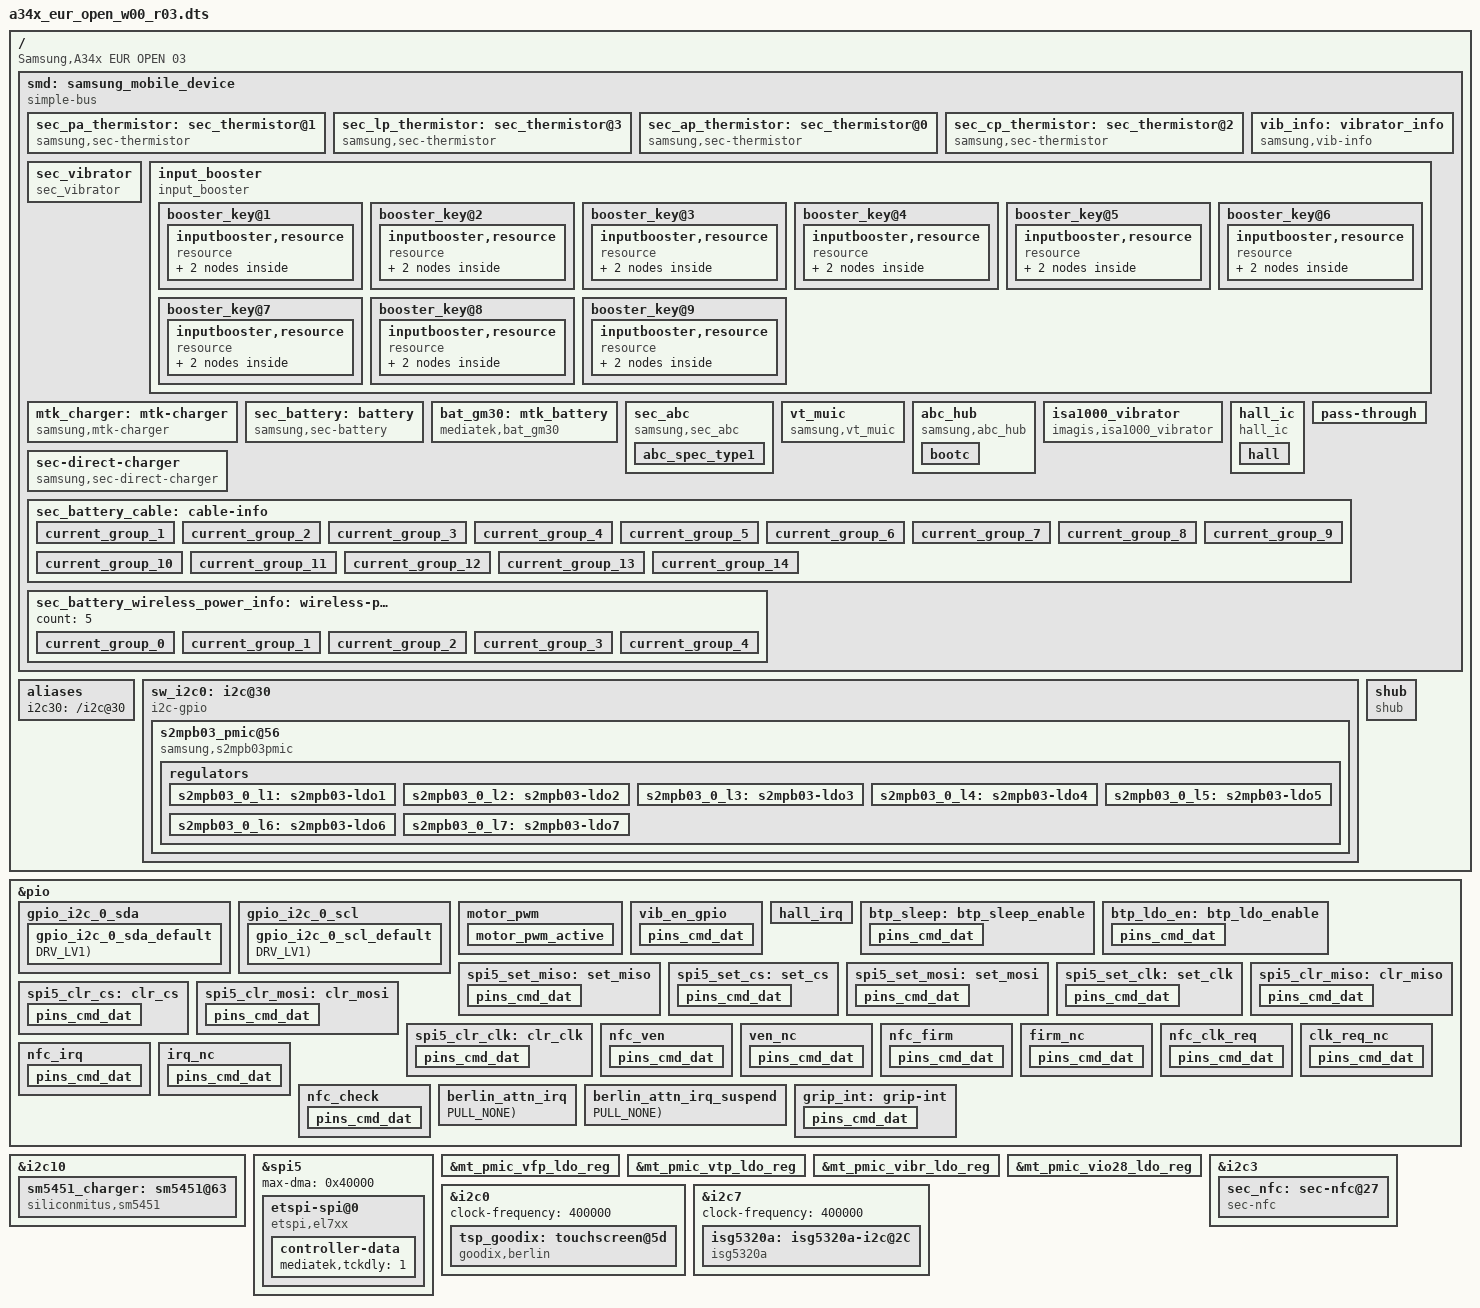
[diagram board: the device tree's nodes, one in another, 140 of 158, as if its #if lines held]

/*
 * Copyright (c) 2018 Samsung Electronics Co., Ltd.
 *              http://www.samsung.com
 *
 * This program is free software; you can redistribute it and/or modify
 * it under the terms of the GNU General Public License version 2 as
 * published by the Free Software Foundation.
*/

/dts-v1/;
/plugin/;
/ {
	fragment@smd {
		target-path = "/";
		__overlay__ {
			smd: samsung_mobile_device {
				compatible = "simple-bus";
			};
		};
	};
};

/* #include "../vibrator_vib_info.dtsi" */           /* From vibrator_vib_info.py */

&smd {
	vib_info: vibrator_info {
		status = "okay";
		compatible = "samsung,vib-info";
		functions = "INTENSITY";
#if 1
		samsung,intensities = <0 2000 4000 6000 8000 10000>;
#else
		samsung,intensities = <>;
#endif

#if 1
		samsung,haptic_intensities = <0 3000 4000 6000 8000 10000>;
#else
		samsung,haptic_intensities = <>;
#endif
	};
};

/* #include "../sec_vibrator.dtsi" */                /* From sec_vibrator.py */

&smd {
	sec_vibrator {
		status = "okay";
		compatible = "sec_vibrator";

		haptic,normal_ratio = <84>;
		haptic,high_temp_ref = <48>;
		haptic,high_temp_ratio = <71>;
	};
};


/* #include "../common/input_booster_mt6877.dtsi" */ /* From input_booster_mt6877.py */
/* Copyright (c) 2019, The Linux Foundation. All rights reserved.
 *
 * This program is free software; you can redistribute it and/or modify
 * it under the terms of the GNU General Public License version 2 and
 * only version 2 as published by the Free Software Foundation.
 *
 * This program is distributed in the hope that it will be useful,
 * but WITHOUT ANY WARRANTY; without even the implied warranty of
 * MERCHANTABILITY or FITNESS FOR A PARTICULAR PURPOSE.  See the
 * GNU General Public License for more details.
 */

&smd {
	input_booster {
		status = "okay";
		compatible = "input_booster";
		resValcount = "2";
		max_resource_count = "3";
		max_cluster_count = "3";
		#address-cells = <1>;
		#size-cells = <0>;

		/* Each Cpu Cluster Start Cpu */
		cpu_cluster_policy = "6,0";

		/* < CPU, DDR, SCHEDBOOST > */
		ib_release_values = "-1,16,0";

		/* Select Allowed Resource Index Group */
		allowed_resources = "0,1";

		booster_key@1 {
			input_booster,label = "key";
			input_booster,type = <0>;	/* BOOSTER_DEVICE_KEY */

			/* Time table */
			input_booster,head_time = <200>;
			input_booster,tail_time = <0>;

			/* Resource Table Sequentially identified with index
			 * CPU's ID & Index : 0
			 * DDR's ID & Index : 1
			*/

			/* Input Booster Resource Frequency */
			inputbooster,resource {
				compatible = "resource";
				resource@1 {
					resource,label = "CPU";
					resource,value = <1540000 0>;
				};

				resource@2 {
					resource,label = "DDR";
					resource,value = <0 0>;
				};
			};
		};

		booster_key@2 {
			input_booster,label = "touchkey";
			input_booster,type = <1>;	/* BOOSTER_DEVICE_TOUCHKEY */

			/* Time table */
			input_booster,head_time = <1>;
			input_booster,tail_time = <300>;

			/* Input Booster Resource Frequency */
			inputbooster,resource {
				compatible = "resource";
				resource@1 {
					resource,label = "CPU";
					resource,value = <0 1540000>;
				};

				resource@2 {
					resource,label = "DDR";
					resource,value = <0 0>;
				};
			};
		};

		booster_key@3 {
			input_booster,label = "touch";
			input_booster,type = <2>;	/* BOOSTER_DEVICE_TOUCH */

			/* Time table */
			input_booster,head_time = <130>;
			input_booster,tail_time = <500>;

			/* Input Booster Resource Frequency */
			inputbooster,resource {
				compatible = "resource";
				resource@1 {
					resource,label = "CPU";
					resource,value = <1140000 1075200>;
				};

				resource@2 {
					resource,label = "DDR";
					resource,value = <4266 4266>;
				};
			};
		};

		booster_key@4 {
			input_booster,label = "multitouch";
			input_booster,type = <3>;	/* BOOSTER_DEVICE_MULTITOUCH */

			/* Time table */
			input_booster,head_time = <1000>;
			input_booster,tail_time = <500>;

			/* Input Booster Resource Frequency */
			inputbooster,resource {
				compatible = "resource";
				resource@1 {
					resource,label = "CPU";
					resource,value = <1140000 1075200>;
				};

				resource@2 {
					resource,label = "DDR";
					resource,value = <4266 4266>;
				};
			};
		};

		booster_key@5 {
			input_booster,label = "keyboard";
			input_booster,type = <4>;	/* BOOSTER_DEVICE_KEYBOARD */

			/* Time table */
			input_booster,head_time = <130>;
			input_booster,tail_time = <130>;

			/* Input Booster Resource Frequency */
			inputbooster,resource {
				compatible = "resource";
				resource@1 {
					resource,label = "CPU";
					resource,value = <1430000 1040000>;
				};

				resource@2 {
					resource,label = "DDR";
					resource,value = <4266 4266>;
				};
			};
		};

		booster_key@6 {
			input_booster,label = "MOUSE";
			input_booster,type = <5>;	/* BOOSTER_DEVICE_MOUSE */

			/* Time table */
			input_booster,head_time = <200>;
			input_booster,tail_time = <300>;

			/* Input Booster Resource Frequency */
			inputbooster,resource {
				compatible = "resource";
				resource@1 {
					resource,label = "CPU";
					resource,value = <1430000 1040000>;
				};

				resource@2 {
					resource,label = "DDR";
					resource,value = <4266 4266>;
				};
			};
		};

		booster_key@7 {
			input_booster,label = "mouse_wheel";
			input_booster,type = <6>;	/* BOOSTER_DEVICE_MOUSE */

			/* Time table */
			input_booster,head_time = <200>;
			input_booster,tail_time = <0>;

			/* Input Booster Resource Frequency */
			inputbooster,resource {
				compatible = "resource";
				resource@1 {
					resource,label = "CPU";
					resource,value = <1430000 0>;
				};

				resource@2 {
					resource,label = "DDR";
					resource,value = <4266 0>;
				};
			};
		};

		booster_key@8 {
			input_booster,label = "pen_hover";
			input_booster,type = <7>;	/* BOOSTER_DEVICE_MOUSE */

			/* Time table */
			input_booster,head_time = <200>;
			input_booster,tail_time = <300>;

			/* Input Booster Resource Frequency */
			inputbooster,resource {
				compatible = "resource";
				resource@1 {
					resource,label = "CPU";
					resource,value = <1430000 1040000>;
				};

				resource@2 {
					resource,label = "DDR";
					resource,value = <0 0>;
				};
			};
		};

		booster_key@9 {
			input_booster,label = "pen";
			input_booster,type = <8>;	/* BOOSTER_DEVICE_MOUSE */

			/* Time table */
			input_booster,head_time = <200>;
			input_booster,tail_time = <600>;

			/* Input Booster Resource Frequency */
			inputbooster,resource {
				compatible = "resource";
				resource@1 {
					resource,label = "CPU";
					resource,value = <1800000 1040000>;
				};

				resource@2 {
					resource,label = "DDR";
					resource,value = <4266 4266>;
				};
			};
		};
		/* If you need to add new key type, add it this position */
	};
};

/* #include "../nc.dtsi" */                          /* From nc.py */
#define LEGO_IS_USE_NC
#define LEGO_IS_USE(x, ...) !defined(LEGO_IS_USE_##x)

/* #include "../sec_pinctrl_wrapper.dtsi" */         /* From sec_pinctrl_wrapper.py */
#define PIN_FUNC_INPUT		input-enable
#define PIN_FUNC_INPUT_WAKEUP	input-enable
#define PIN_FUNC_OUTPUT		output-enable
#define PIN_FUNC_OUTPUT_HIGH		output-high
#define PIN_FUNC_OUTPUT_LOW		output-low

#define PIN_PULL_NONE	bias-disable
#define PIN_PULL_DOWN	bias-pull-down
#define PIN_PULL_UP	bias-pull-up
#define PIN_PULL_OPEN	bias-high-impedance

/*
 * MTK_DRIVE_2mA  2
 * MTK_DRIVE_4mA  4
 * MTK_DRIVE_6mA  6
 * MTK_DRIVE_8mA  8
 * MTK_DRIVE_10mA 10
 * MTK_DRIVE_12mA 12
 * MTK_DRIVE_14mA 14
 * MTK_DRIVE_16mA 16
 */

#define PIN_DRV_LV1	2
#define PIN_DRV_LV2	4
#define PIN_DRV_LV3	6
#define PIN_DRV_LV4	8
#define PIN_DRV_LV5	10
#define PIN_DRV_LV6	12
#define PIN_DRV_LV7	14
#define PIN_DRV_LV8	16

#define PIN_EXPAND(pin) #pin

#define SEC_GPIO(src, type, num)	PIN_EXPAND(gpio##num)
#define SEC_GPIO_REF(src, type, num)	&type num
#define SEC_GPIO_NUM(src, type, num)	num
#define SEC_GPIO_TYPE(src, type, num)	&type
#define SEC_GPIO_PHANDLE_ACTIVE(src, type, num)	SEC_GPIO_PHANDLE(type, num, active)
#define SEC_GPIO_PHANDLE_SLEEP(src, type, num)	SEC_GPIO_PHANDLE(type, num, sleep)
#define SEC_GPIO_PHANDLE(type, num, mode)	type##_##num##_##mode

#define MTK_PINMUX(gpio, func) (MTK_PIN_NO(gpio) | func)

#define GPIO_CONFIG(_src, _type, _num, _func)		\
	pins_cmd_dat{					\
		pinmux = <MTK_PINMUX(SEC_GPIO_NUM(_src, _type, _num), 0)>;	\
		PIN_ ##_func;		\
	}

#define GPIO_CONFIG_PUD(_src, _type, _num, _func, _pull)	\
	pins_cmd_dat{					\
		pinmux = <MTK_PINMUX(SEC_GPIO_NUM(_src, _type, _num), 0)>;	\
		PIN_ ##_pull;				\
		PIN_ ##_func;		\
	}

#define GPIO_CONFIG_PUD_DRV(_src, _type, _num, _func, _pull, _drv)	\
	pins_cmd_dat{					\
		pinmux = <MTK_PINMUX(SEC_GPIO_NUM(_src, _type, _num), 0)>;	\
		PIN_ ##_pull;				\
		PIN_ ##_func;		\
		drive-strength = <PIN_ ##_drv>;	\
	}

#define SEC_ADC(type, num) <&type num>
#define SEC_ADC_OPT(type, num) ,<&type num>
#define SEC_ADC_NUM(type, num) <num>

/* #include "../mtk_charger.dtsi" */                 /* From mtk_charger.py */

&smd {
	mtk_charger: mtk-charger {
		compatible = "samsung,mtk-charger";
#if defined(CONFIG_SEC_FACTORY)
		charger,vbus_min_charger_voltage = <4200000>;
		charger,vbus_normal_mivr_voltage = <4200000>;
#else
		charger,vbus_min_charger_voltage = <4400000>;
		charger,vbus_normal_mivr_voltage = <4400000>;
#endif
		charger,gpio_ilim = <&pio 140 0x0>;
		charger,gpio_chgenb = <&pio 135 0x0>;
		charger,max_icl = <3250>;
		charger,ib_fcc = <100>;
	};

	battery {
		battery,otg_name = "mtk-otg";
	};
};

/* /home/dpi/qb5_8814/workspace/P4_1716/android/kernel/kmodule/battery/suwon/charger/mtk_charger/mtk_charger.a34x.dtsi */

&smd {
	mtk_charger: mtk-charger {
		charger,gpio_chgenb = <&pio 142 0x0>;
		charger,chgilm_en = <0>;
	};
};

/* /home/dpi/qb5_8814/workspace/P4_1716/android/kernel/kmodule/battery/suwon/charger/mtk_charger/mtk_charger.a34x.01.dtsi */

&smd {
	mtk_charger: mtk-charger {
		charger,gpio_chgenb = <&pio 27 0x0>;
		charger,chgenb_en = <0>;
	};
};

/* #include "../mtk_fuelgauge.dtsi" */               /* From mtk_fuelgauge.py */
&smd {
	battery {
		battery,fuelgauge_name = "mtk-fg-battery";
	};

	/* battery_prop.dtsi */
	bat_gm30: mtk_battery{
		compatible = "mediatek,bat_gm30";
		DIFFERENCE_FULLOCV_ITH = <(300)>;
	/*	Charging termination current*/
		SHUTDOWN_1_TIME = <(60)>;
	/*	If ui_soc shows 1% more than X minites, system will shutdown*/
		KEEP_100_PERCENT = <(1)>;
	/*	The ui_soc will keep 100% until SOC drop X percents after unplugged */
		R_FG_VALUE = <(5)>;
	/*	R_sense resistance*/
		EMBEDDED_SEL = <(0)>;
	/*	Configures whether using embedded battery or not*/
		PMIC_SHUTDOWN_CURRENT = <(20)>;
	/*	System shutdown current*/
		FG_METER_RESISTANCE = <(100)>;
	/*	The resistance of PCB*/
		CAR_TUNE_VALUE = <(99)>;
	/*	Tune value for current measurement*/
		PMIC_MIN_VOL = <(33500)>;
	/*	vboot voltage for gauge 0%*/
		POWERON_SYSTEM_IBOOT = <(500)>;
	/*	power on system iboot*/
		SHUTDOWN_GAUGE0 = <(0)>;
	/*	Shutdown condition2 switch*/
		SHUTDOWN_GAUGE0_VOLTAGE = <(34000)>;
	/*	shutdown gauge 0% voltage*/
		TEMPERATURE_T0 = <(50)>;
	/*	Battery temperature T0*/
		TEMPERATURE_T1 = <(25)>;
	/*	Battery temperature T1*/
		TEMPERATURE_T2 = <(10)>;
	/*	Battery temperature T2*/
		TEMPERATURE_T3 = <(0)>;
	/*	Battery temperature T3*/
		TEMPERATURE_T4 = <(-10)>;
	/*	Battery temperature T4*/
		TEMPERATURE_T5 = <(-20)>;
	/*	Battery temperature T5*/
		g_FG_PSEUDO100_T0 = <(93)>;
	/*	Pseudo 100% percentage at T0*/
		g_FG_PSEUDO100_T1 = <(93)>;
	/*	Pseudo 100% percentage at T1*/
		g_FG_PSEUDO100_T2 = <(93)>;
	/*	Pseudo 100% percentage at T2*/
		g_FG_PSEUDO100_T3 = <(93)>;
	/*	Pseudo 100% percentage at T3*/
		g_FG_PSEUDO100_T4 = <(93)>;
	/*	Pseudo 100% percentage at T4*/
		g_FG_PSEUDO100_T5 = <(93)>;
	/*	Pseudo 100% percentage at T4*/
		Q_MAX_SYS_VOLTAGE_BAT0 = <(3350)>;
	/*	Pseudo1 for hide percentage*/
		Q_MAX_SYS_VOLTAGE_BAT1 = <(3350)>;
	/*	Pseudo1 for hide percentage*/
		Q_MAX_SYS_VOLTAGE_BAT2 = <(3350)>;
	/*	Pseudo1 for hide percentage*/
		Q_MAX_SYS_VOLTAGE_BAT3 = <(3350)>;
	/*	Pseudo1 for hide percentage*/
		COM_FG_METER_RESISTANCE = <(100)>;
	/*	compensate The resistance of PCB*/
		COM_R_FG_VALUE = <(0)>;
	/*	compensate R_sense resistance*/
		enable_tmp_intr_suspend = <(0)>;
	/* Enable update temp when suspend */
		ACTIVE_TABLE = <(6)>;
	/* Table numbers per battery*/
		MULTI_TEMP_GAUGE0 = <(1)>;
	/* Multi gauge0 enable*/
		HWOCV_OLDOCV_DIFF = <(100)>;
	/* Diff of HWOCV and SWOCV*/

	/* battery_table.dtsi*/
	battery0_profile_t0_num = <100>;
	battery0_profile_t0_col = <3>;
	battery0_profile_t0 =
	<
	0       43520   850
	486     43380   866
	972     43251   875
	1458    43130   897
	1944    43004   875
	2430    42881   875
	2916    42760   875
	3402    42644   875
	3888    42530   900
	4375    42407   875
	4861    42293   881
	5347    42178   900
	5833    42054   875
	6319    41941   897
	6805    41820   875
	7291    41714   875
	7777    41601   900
	8263    41485   875
	8749    41372   875
	9235    41267   897
	9721    41155   875
	10207   41051   875
	10693   40945   875
	11179   40837   884
	11665   40739   875
	12152   40642   900
	12638   40542   894
	13124   40446   919
	13610   40350   900
	14096   40253   900
	14582   40162   919
	15068   40070   925
	15554   39979   925
	16040   39898   941
	16526   39817   950
	17012   39736   950
	17498   39655   962
	17984   39573   975
	18470   39492   975
	18956   39411   1000
	19442   39329   1025
	19928   39210   975
	20415   39078   938
	20901   38949   878
	21387   38849   875
	21873   38773   850
	22359   38699   850
	22845   38635   850
	23331   38580   850
	23817   38521   850
	24303   38472   850
	24789   38423   850
	25275   38374   875
	25761   38326   850
	26247   38285   869
	26733   38239   850
	27219   38200   875
	27705   38157   866
	28192   38115   868
	28678   38082   872
	29164   38050   875
	29650   38007   853
	30136   37975   875
	30622   37952   900
	31108   37919   900
	31594   37887   900
	32080   37865   907
	32566   37841   925
	33052   37810   925
	33538   37765   900
	34024   37684   861
	34510   37614   865
	34996   37550   851
	35482   37511   859
	35968   37465   857
	36455   37424   853
	36941   37374   850
	37427   37337   875
	37913   37304   875
	38399   37272   875
	38885   37230   875
	39371   37185   900
	39857   37120   875
	40343   37063   875
	40829   37004   888
	41315   36942   879
	41801   36861   881
	42287   36806   860
	42773   36790   875
	43259   36780   891
	43745   36767   907
	44232   36751   948
	44718   36719   976
	45204   36643   1018
	45690   36372   937
	46176   35944   969
	46662   35387   1000
	47148   34581   1041
	47634   33318   1181
	48120   30130   10325
	>;
	battery0_profile_t1_num = <100>;
	battery0_profile_t1_col = <3>;
	battery0_profile_t1 =
	<
	0       43320   1450
	486     43164   1450
	972     43033   1475
	1458    42911   1475
	1944    42789   1475
	2430    42671   1475
	2916    42550   1456
	3402    42434   1475
	3888    42320   1475
	4375    42197   1440
	4861    42083   1431
	5347    41968   1428
	5833    41854   1437
	6319    41741   1428
	6805    41628   1431
	7291    41514   1425
	7777    41401   1425
	8263    41295   1425
	8749    41184   1407
	9235    41078   1403
	9721    40975   1412
	10207   40871   1425
	10693   40765   1425
	11179   40667   1416
	11665   40569   1425
	12152   40475   1450
	12638   40382   1450
	13124   40277   1450
	13610   40190   1450
	14096   40093   1447
	14582   40002   1444
	15068   39920   1460
	15554   39839   1450
	16040   39758   1450
	16526   39687   1500
	17012   39606   1500
	17498   39525   1500
	17984   39443   1504
	18470   39354   1525
	18956   39243   1490
	19442   39109   1425
	19928   38980   1344
	20415   38875   1319
	20901   38787   1300
	21387   38719   1313
	21873   38654   1300
	22359   38589   1300
	22845   38535   1290
	23331   38480   1300
	23817   38431   1291
	24303   38384   1300
	24789   38343   1300
	25275   38294   1300
	25761   38257   1303
	26247   38217   1325
	26733   38182   1309
	27219   38140   1325
	27705   38107   1341
	28192   38075   1332
	28678   38042   1350
	29164   38010   1350
	29650   37987   1375
	30136   37955   1375
	30622   37926   1375
	31108   37900   1376
	31594   37877   1384
	32080   37855   1400
	32566   37822   1378
	33052   37790   1375
	33538   37747   1375
	34024   37707   1356
	34510   37672   1360
	34996   37630   1351
	35482   37591   1359
	35968   37552   1350
	36455   37512   1372
	36941   37480   1375
	37427   37447   1375
	37913   37414   1394
	38399   37368   1385
	38885   37310   1376
	39371   37248   1393
	39857   37192   1400
	40343   37134   1423
	40829   37063   1412
	41315   36975   1425
	41801   36935   1425
	42287   36920   1460
	42773   36910   1475
	43259   36894   1500
	43745   36867   1514
	44232   36833   1573
	44718   36727   1613
	45204   36421   1607
	45690   35937   1688
	46176   35299   1804
	46662   34415   1951
	47148   32710   2488
	47634   30570   11550
	48120   30570   11550
	>;
	battery0_profile_t2_num = <100>;
	battery0_profile_t2_col = <3>;
	battery0_profile_t2 =
	<
	0       43000   3200
	486     42808   3293
	972     42661   3412
	1458    42531   3472
	1944    42404   3476
	2430    42281   3478
	2916    42160   3481
	3402    42044   3484
	3888    41930   3475
	4375    41817   3485
	4861    41695   3456
	5347    41579   3431
	5833    41474   3450
	6319    41361   3425
	6805    41255   3425
	7291    41144   3425
	7777    41041   3425
	8263    40931   3416
	8749    40834   3407
	9235    40737   3425
	9721    40640   3425
	10207   40541   3444
	10693   40435   3419
	11179   40337   3425
	11665   40229   3375
	12152   40138   3391
	12638   40047   3381
	13124   39957   3378
	13610   39875   3400
	14096   39794   3375
	14582   39712   3375
	15068   39640   3415
	15554   39559   3425
	16040   39472   3409
	16526   39382   3425
	17012   39269   3381
	17498   39146   3350
	17984   39008   3268
	18470   38894   3225
	18956   38801   3200
	19442   38720   3200
	19928   38655   3200
	20415   38590   3200
	20901   38534   3222
	21387   38479   3225
	21873   38426   3250
	22359   38377   3250
	22845   38329   3275
	23331   38280   3275
	23817   38241   3300
	24303   38202   3325
	24789   38162   3347
	25275   38130   3363
	25761   38087   3378
	26247   38055   3400
	26733   38022   3425
	27219   37990   3425
	27705   37967   3466
	28192   37935   3500
	28678   37911   3500
	29164   37885   3525
	29650   37859   3528
	30136   37842   3569
	30622   37822   3600
	31108   37800   3601
	31594   37784   3641
	32080   37757   3657
	32566   37732   3697
	33052   37700   3700
	33538   37667   3728
	34024   37627   3750
	34510   37592   3795
	34996   37559   3850
	35482   37517   3866
	35968   37482   3932
	36455   37434   3972
	36941   37374   4026
	37427   37314   4104
	37913   37249   4144
	38399   37190   4235
	38885   37119   4325
	39371   37028   4398
	39857   36965   4501
	40343   36932   4666
	40829   36905   4816
	41315   36877   5048
	41801   36845   5310
	42287   36790   5653
	42773   36689   6028
	43259   36466   6433
	43745   36033   6914
	44232   35419   7720
	44718   34544   8974
	45204   33115   11297
	45690   30950   12525
	46176   30950   12525
	46662   30950   12525
	47148   30950   12525
	47634   30950   12525
	48120   30950   12525
	>;
	battery0_profile_t3_num = <100>;
	battery0_profile_t3_col = <3>;
	battery0_profile_t3 =
	<
	0       42520   5950
	486     42262   6183
	972     42098   6518
	1458    41961   6640
	1944    41824   6714
	2430    41701   6753
	2916    41580   6775
	3402    41464   6816
	3888    41350   6825
	4375    41237   6840
	4861    41123   6825
	5347    41017   6847
	5833    40909   6825
	6319    40812   6847
	6805    40715   6844
	7291    40604   6825
	7777    40501   6825
	8263    40385   6784
	8749    40274   6782
	9235    40177   6800
	9721    40080   6800
	10207   39984   6778
	10693   39903   6781
	11179   39821   6784
	11665   39739   6800
	12152   39658   6791
	12638   39587   6825
	13124   39497   6803
	13610   39410   6813
	14096   39312   6797
	14582   39196   6756
	15068   39069   6680
	15554   38949   6625
	16040   38836   6584
	16526   38747   6569
	17012   38666   6550
	17498   38600   6575
	17984   38536   6579
	18470   38479   6600
	18956   38418   6635
	19442   38370   6675
	19928   38321   6691
	20415   38275   6706
	20901   38234   6725
	21387   38194   6750
	21873   38156   6775
	22359   38115   6794
	22845   38082   6835
	23331   38050   6850
	23817   38018   6891
	24303   37984   6907
	24789   37952   6925
	25275   37930   6975
	25761   37909   7003
	26247   37892   7044
	26733   37876   7084
	27219   37860   7125
	27705   37843   7183
	28192   37827   7214
	28678   37811   7295
	29164   37795   7351
	29650   37777   7407
	30136   37752   7488
	30622   37722   7544
	31108   37689   7626
	31594   37657   7723
	32080   37622   7813
	32566   37582   7939
	33052   37540   8076
	33538   37495   8238
	34024   37437   8422
	34510   37374   8610
	34996   37309   8853
	35482   37238   9080
	35968   37170   9352
	36455   37096   9676
	36941   37004   10017
	37427   36935   10393
	37913   36894   10858
	38399   36862   11389
	38885   36830   11982
	39371   36791   12670
	39857   36740   13453
	40343   36656   14301
	40829   36424   15025
	41315   35986   15823
	41801   35349   16953
	42287   34442   18475
	42773   33430   18575
	43259   33430   18575
	43745   33430   18575
	44232   33430   18575
	44718   33430   18575
	45204   33430   18575
	45690   33430   18575
	46176   33430   18575
	46662   33430   18575
	47148   33430   18575
	47634   33430   18575
	48120   33430   18575
	>;
	battery0_profile_t4_num = <100>;
	battery0_profile_t4_col = <3>;
	battery0_profile_t4 =
	<
	0       42010   11330
	486     41738   11604
	972     41429   12066
	1458    41171   12469
	1944    40989   12751
	2430    40838   12878
	2916    40700   12919
	3402    40570   12916
	3888    40440   12875
	4375    40311   12819
	4861    40181   12744
	5347    40058   12703
	5833    39949   12675
	6319    39842   12650
	6805    39745   12650
	7291    39648   12616
	7777    39541   12526
	8263    39441   12509
	8749    39332   12437
	9235    39227   12378
	9721    39115   12312
	10207   39013   12272
	10693   38923   12250
	11179   38841   12216
	11665   38759   12200
	12152   38694   12184
	12638   38622   12175
	13124   38565   12175
	13610   38510   12200
	14096   38456   12178
	14582   38407   12200
	15068   38358   12210
	15554   38310   12225
	16040   38261   12241
	16526   38215   12256
	17012   38174   12297
	17498   38140   12325
	17984   38097   12329
	18470   38065   12350
	18956   38032   12375
	19442   38010   12450
	19928   37977   12475
	20415   37955   12506
	20901   37931   12568
	21387   37905   12626
	21873   37874   12675
	22359   37855   12770
	22845   37832   12819
	23331   37800   12900
	23817   37778   13031
	24303   37744   13121
	24789   37712   13242
	25275   37670   13327
	25761   37626   13460
	26247   37577   13639
	26733   37535   13728
	27219   37480   13875
	27705   37420   14031
	28192   37359   14202
	28678   37294   14386
	29164   37230   14552
	29650   37155   14720
	30136   37090   14944
	30622   37028   15148
	31108   36979   15354
	31594   36947   15613
	32080   36905   15847
	32566   36863   16130
	33052   36790   16376
	33538   36673   16644
	34024   36429   16891
	34510   36018   17215
	34996   35399   17761
	35482   34431   18699
	35968   32802   17069
	36455   31080   12750
	36941   31080   12750
	37427   31080   12750
	37913   31080   12750
	38399   31080   12750
	38885   31080   12750
	39371   31080   12750
	39857   31080   12750
	40343   31080   12750
	40829   31080   12750
	41315   31080   12750
	41801   31080   12750
	42287   31080   12750
	42773   31080   12750
	43259   31080   12750
	43745   31080   12750
	44232   31080   12750
	44718   31080   12750
	45204   31080   12750
	45690   31080   12750
	46176   31080   12750
	46662   31080   12750
	47148   31080   12750
	47634   31080   12750
	48120   31080   12750
	>;
	battery0_profile_t5_num = <100>;
	battery0_profile_t5_col = <3>;
	battery0_profile_t5 =
	<
	0       40920   10780
	483     40610   11233
	967     40337   12231
	1450    40095   12975
	1933    39872   13686
	2417    39674   14479
	2900    39510   15208
	3383    39378   15667
	3867    39258   15931
	4350    39150   16075
	4833    39042   16178
	5317    38929   16164
	5800    38830   16208
	6283    38733   16319
	6767    38652   16378
	7250    38573   16404
	7733    38509   16464
	8217    38444   16519
	8700    38390   16625
	9183    38335   16666
	9667    38292   16706
	10150   38244   16725
	10633   38200   16750
	11117   38158   16752
	11600   38126   16810
	12083   38087   16833
	12567   38052   16965
	13050   38019   16990
	13533   37987   17100
	14017   37955   17176
	14500   37919   17218
	14983   37880   17323
	15467   37838   17390
	15950   37794   17510
	16433   37738   17550
	16917   37683   17714
	17400   37629   17828
	17883   37564   17981
	18367   37500   18070
	18850   37427   18222
	19333   37361   18385
	19817   37286   18407
	20300   37222   18563
	20783   37158   18764
	21267   37093   18919
	21750   37039   19080
	22233   36974   19247
	22717   36910   19451
	23200   36824   19655
	23683   36692   19921
	24167   36470   20134
	24650   36118   20420
	25133   35546   20803
	25617   34662   21167
	26100   33270   18200
	26583   32530   16450
	27067   32530   16450
	27550   32530   16450
	28033   32530   16450
	28517   32530   16450
	29000   32530   16450
	29483   32530   16450
	29967   32530   16450
	30450   32530   16450
	30933   32530   16450
	31417   32530   16450
	31900   32530   16450
	32383   32530   16450
	32867   32530   16450
	33350   32530   16450
	33833   32530   16450
	34317   32530   16450
	34800   32530   16450
	35283   32530   16450
	35767   32530   16450
	36250   32530   16450
	36733   32530   16450
	37217   32530   16450
	37700   32530   16450
	38183   32530   16450
	38667   32530   16450
	39150   32530   16450
	39633   32530   16450
	40117   32530   16450
	40600   32530   16450
	41083   32530   16450
	41567   32530   16450
	42050   32530   16450
	42533   32530   16450
	43017   32530   16450
	43500   32530   16450
	43983   32530   16450
	44467   32530   16450
	44950   32530   16450
	45433   32530   16450
	45917   32530   16450
	46400   32530   16450
	46883   32530   16450
	47367   32530   16450
	47850   32530   16450
	>;

	/* battery_prop_dim2_ext.dtsi */
	/*vboot voltage for gauge 0%*/
	g_PMIC_MIN_VOL_row = <4>;
	g_PMIC_MIN_VOL_col = <10>;
	g_PMIC_MIN_VOL =
	<
		32700  32700  32700  32700
		32700  32700  32700  32700
		32700  32700  32700  32700
		32200  32200  32200  32200
		31000  31000  31000  31000
		31500  31500  31500  31500
		31000  31000  31000  31000
		31000  31000  31000  31000
		31000  31000  31000  31000
		31000  31000  31000  31200
	>;
	/*boot_up current for gauge 0%*/
	g_PON_SYS_IBOOT_row = <4>;
	g_PON_SYS_IBOOT_col = <10>;
	g_PON_SYS_IBOOT =
	<
		5000  5000  5000  5000
		5000  5000  5000  5000
		5000  5000  5000  5000
		5000  5000  5000  5000
		5000  5000  5000  5000
		5000  5000  5000  5000
		5000  5000  5000  5000
		5000  5000  5000  5000
		5000  5000  5000  5000
		5000  5000  5000  5000
	>;
	/*Pseudo1 hide percentage*/
	g_QMAX_SYS_VOL_row = <4>;
	g_QMAX_SYS_VOL_col = <10>;
	g_QMAX_SYS_VOL =
	<
		33600  33600  33600  33600
		33600  33600  33600  33600
		33600  33600  33600  33600
		33600  33600  33600  33600
		33600  33600  33600  33600
		32500  32500  32500  32500
		32800  32800  32800  32800
		32800  32800  32800  32800
		32800  32800  32800  32800
		32800  32800  32800  32800
	>;
	/*Pseudo100 percentage setting*/
	g_FG_PSEUDO100_row = <4>;
	g_FG_PSEUDO100_col = <10>;
	g_FG_PSEUDO100 =
	<
		91  100  100  100
		91  100  100  100
		91  100  100  100
		91  100  100  100
		91  100  100  100
		91  100  100  100
		100  100  100  100
		100  100  100  100
		100  100  100  100
		100  100  100  100
	>;

	};
};

/* /home/dpi/qb5_8814/workspace/P4_1716/android/kernel/kmodule/battery/suwon/fuelgauge/mtk_fuelgauge/mtk_fuelgauge.a34x.dtsi */
&smd {
	battery {
		battery,fuelgauge_name = "mtk-fg-battery";
	};

	/* battery_prop.dtsi */
bat_gm30: mtk_battery{
	compatible = "mediatek,bat_gm30";

	RBAT_TYPE = <(100)>;
	RBAT_PULL_UP_R = <(100000)>;

	rbat_temperature_table_num = <21>;
	rbat_battery_temperature =
	<
		(-40) 4397119
		(-35) 3088598
		(-30) 2197225
		(-25) 1581880
		(-20) 1151036
		(-15) 846578
		(-10) 628988
		(-5) 471632
		0 357011
		5 272499
		10 209709
		15 162650
		20 127080
		25 100000
		30 79221
		35 63167
		40 50676
		45 40903
		50 33194
		55 27090
		60 22224 >;
/* battery temperature table type - NTC table */
	BatteryID_GPIO_1 = <&pio 21 0>;
	BatteryID_GPIO = <&pio 22 0>;
/* Battery ID distinction */
	DIFFERENCE_FULLOCV_ITH = <(300)>; /* M53 : 250mA +50mA */
/*	Charging termination current*/
	SHUTDOWN_1_TIME = <(60)>;
/*	If ui_soc shows 1% more than X minites, system will shutdown*/
	KEEP_100_PERCENT = <(1)>;
/*	The ui_soc will keep 100% until SOC drop X percents after unplugged*/
	R_FG_VALUE = <(5)>;
/*	R_sense resistance*/
	EMBEDDED_SEL = <(0)>;
/*	Configures whether using embedded battery or not*/
	PMIC_SHUTDOWN_CURRENT = <(20)>;
/*	System shutdown current*/
	FG_METER_RESISTANCE = <(100)>;
/*	The resistance of PCB*/
	CAR_TUNE_VALUE = <(98)>;
/*	Tune value for current measurement*/
	PMIC_MIN_VOL = <(33500)>;
/*	vboot voltage for gauge 0%*/
	POWERON_SYSTEM_IBOOT = <(500)>;
/*	power on system iboot*/
	SHUTDOWN_GAUGE0 = <(0)>;
/*	Shutdown condition2 switch*/
	SHUTDOWN_GAUGE0_VOLTAGE = <(34000)>;
/*	shutdown gauge 0% voltage*/
	TEMPERATURE_T0 = <(50)>;
/*	Battery temperature T0*/
	TEMPERATURE_T1 = <(25)>;
/*	Battery temperature T1*/
	TEMPERATURE_T2 = <(10)>;
/*	Battery temperature T2*/
	TEMPERATURE_T3 = <(0)>;
/*	Battery temperature T3*/
	TEMPERATURE_T4 = <(-10)>;
/*	Battery temperature T4*/
	TEMPERATURE_T5 = <(-20)>;
/*	Battery temperature T5*/
	g_FG_PSEUDO100_T0 = <(100)>;
/*	Pseudo 100% percentage at T0*/
	g_FG_PSEUDO100_T1 = <(100)>;
/*	Pseudo 100% percentage at T1*/
	g_FG_PSEUDO100_T2 = <(100)>;
/*	Pseudo 100% percentage at T2*/
	g_FG_PSEUDO100_T3 = <(100)>;
/*	Pseudo 100% percentage at T3*/
	g_FG_PSEUDO100_T4 = <(100)>;
/*	Pseudo 100% percentage at T4*/
	g_FG_PSEUDO100_T5 = <(100)>;
/*	Pseudo 100% percentage at T4*/
	Q_MAX_SYS_VOLTAGE_BAT0 = <(3350)>;
/*	Pseudo1 for hide percentage*/
	Q_MAX_SYS_VOLTAGE_BAT1 = <(3350)>;
/*	Pseudo1 for hide percentage*/
	Q_MAX_SYS_VOLTAGE_BAT2 = <(3350)>;
/*	Pseudo1 for hide percentage*/
	Q_MAX_SYS_VOLTAGE_BAT3 = <(3350)>;
/*	Pseudo1 for hide percentage*/
	COM_FG_METER_RESISTANCE = <(100)>;
/*	compensate The resistance of PCB*/
	COM_R_FG_VALUE = <(0)>;
/*	compensate R_sense resistance*/
	enable_tmp_intr_suspend = <(0)>;
/* Enable update temp when suspend */
	ACTIVE_TABLE = <(6)>;
/* Table numbers per battery*/
	MULTI_TEMP_GAUGE0 = <(1)>;
/* Multi gauge0 enable*/
	HWOCV_OLDOCV_DIFF = <(100)>;
/* Diff of HWOCV and SWOCV*/
	UI_FULL_LIMIT_EN = <(1)>;
	UI_FULL_LIMIT_SOC0 = <(9545)>;
	UI_FULL_LIMIT_ITH0 = <(12000)>;
	UI_FULL_LIMIT_SOC1 = <(9645)>;
	UI_FULL_LIMIT_ITH1 = <(10000)>;
	UI_FULL_LIMIT_SOC2 = <(9745)>;
	UI_FULL_LIMIT_ITH2 = <(8000)>;
	UI_FULL_LIMIT_SOC3 = <(9845)>;
	UI_FULL_LIMIT_ITH3 = <(6500)>;
	UI_FULL_LIMIT_SOC4 = <(9945)>;
	UI_FULL_LIMIT_ITH4 = <(5300)>;
/* Using current to limit uisoc in 100% case*/
	UI_LOW_LIMIT_EN = <(1)>;
	UI_LOW_LIMIT_SOC0 = <(100)>;
	UI_LOW_LIMIT_VTH0 = <(34000)>;
	UI_LOW_LIMIT_SOC1 = <(100)>;
	UI_LOW_LIMIT_VTH1 = <(34000)>;
	UI_LOW_LIMIT_SOC2 = <(100)>;
	UI_LOW_LIMIT_VTH2 = <(34000)>;
	UI_LOW_LIMIT_SOC3 = <(100)>;
	UI_LOW_LIMIT_VTH3 = <(34000)>;
	UI_LOW_LIMIT_SOC4 = <(100)>;
	UI_LOW_LIMIT_VTH4 = <(34000)>;
/* using voltage to limit uisoc in 1% case */
	DYNAMIC_CV_FACTOR = <(100)>;
/* Dynamic CV offset */
	CHARGER_IEOC = <(250)>;
/* Charger termination current for Dynamic CV */

/* battery_table.dtsi*/
battery0_profile_t0_num = <100>;
battery0_profile_t0_col = <3>;
battery0_profile_t0 =
<
0       43990   475
474     43854   475
948     43739   500
1423    43628   500
1897    43515   500
2371    43404   500
2845    43289   488
3320    43182   500
3794    43062   500
4268    42949   500
4742    42831   500
5217    42708   498
5691    42587   501
6165    42471   510
6639    42354   525
7114    42228   506
7588    42111   516
8062    41992   524
8536    41876   525
9011    41751   503
9485    41640   525
9959    41529   532
10433   41419   550
10908   41298   525
11382   41185   525
11856   41081   541
12330   40974   550
12805   40863   530
13279   40762   565
13753   40652   526
14227   40551   550
14702   40450   550
15176   40355   569
15650   40260   575
16124   40165   575
16598   40070   575
17073   39985   600
17547   39897   616
18021   39806   607
18495   39719   625
18970   39628   625
19444   39529   625
19918   39397   585
20392   39246   525
20867   39127   506
21341   39032   509
21815   38952   501
22289   38879   500
22764   38816   500
23238   38752   500
23712   38689   500
24186   38633   500
24661   38576   500
25135   38519   500
25609   38471   500
26083   38424   525
26558   38376   525
27032   38329   525
27506   38280   525
27980   38239   514
28455   38197   525
28929   38158   525
29403   38121   525
29877   38082   547
30352   38051   550
30826   38018   552
31300   37980   558
31774   37945   550
32248   37913   550
32723   37874   555
33197   37810   500
33671   37731   514
34145   37654   505
34620   37599   506
35094   37550   500
35568   37511   523
36042   37455   500
36517   37417   525
36991   37369   508
37465   37334   525
37939   37294   503
38414   37257   525
38888   37199   524
39362   37136   500
39836   37074   505
40311   37018   505
40785   36951   510
41259   36872   525
41733   36825   489
42208   36819   522
42682   36803   500
43156   36797   525
43630   36772   525
44105   36746   550
44579   36662   550
45053   36398   566
45527   36003   625
46002   35496   665
46476   34819   735
46950   33830   850
>;
battery0_profile_t1_num = <100>;
battery0_profile_t1_col = <3>;
battery0_profile_t1 =
<
0       43900   750
474     43774   750
948     43669   800
1423    43558   781
1897    43449   784
2371    43344   800
2845    43234   800
3320    43122   800
3794    43002   800
4268    42889   800
4742    42771   800
5217    42648   800
5691    42527   801
6165    42411   810
6639    42286   800
7114    42168   800
7588    42051   800
8062    41932   800
8536    41811   800
9011    41701   803
9485    41583   807
9959    41469   807
10433   41359   825
10908   41248   825
11382   41135   825
11856   41031   841
12330   40924   850
12805   40813   850
13279   40712   850
13753   40611   874
14227   40511   875
14702   40410   879
15176   40307   881
15650   40210   883
16124   40115   900
16598   40030   925
17073   39935   925
17547   39847   925
18021   39754   925
18495   39667   946
18970   39564   925
19444   39459   924
19918   39317   845
20392   39186   796
20867   39075   775
21341   38982   741
21815   38912   749
22289   38839   738
22764   38776   750
23238   38712   733
23712   38659   743
24186   38603   747
24661   38546   725
25135   38499   750
25609   38451   750
26083   38404   750
26558   38356   750
27032   38319   750
27506   38270   750
27980   38233   750
28455   38196   771
28929   38155   750
29403   38124   775
29877   38092   797
30352   38061   787
30826   38028   798
31300   37997   792
31774   37965   800
32248   37933   779
32723   37902   800
33197   37860   775
33671   37817   761
34145   37766   750
34620   37727   750
35094   37690   750
35568   37642   727
36042   37595   725
36517   37558   727
36991   37519   733
37465   37484   750
37939   37453   750
38414   37407   750
38888   37349   750
39362   37286   750
39836   37234   755
40311   37178   775
40785   37101   750
41259   37022   774
41733   36975   764
42208   36960   775
42682   36953   775
43156   36937   782
43630   36921   822
44105   36886   825
44579   36822   873
45053   36575   866
45527   36160   911
46002   35630   990
46476   34925   1123
46950   33930   1425
>;
battery0_profile_t2_num = <100>;
battery0_profile_t2_col = <3>;
battery0_profile_t2 =
<
0       43620   1525
474     43458   1554
948     43337   1625
1423    43218   1644
1897    43095   1659
2371    42975   1675
2845    42859   1675
3320    42742   1675
3794    42622   1692
4268    42499   1675
4742    42381   1696
5217    42259   1686
5691    42137   1675
6165    42017   1675
6639    41904   1695
7114    41785   1675
7588    41671   1691
8062    41554   1699
8536    41442   1700
9011    41331   1725
9485    41220   1707
9959    41109   1725
10433   40999   1725
10908   40892   1725
11382   40788   1726
11856   40685   1750
12330   40584   1775
12805   40481   1775
13279   40376   1785
13753   40281   1800
14227   40177   1800
14702   40082   1800
15176   39985   1819
15650   39890   1825
16124   39786   1802
16598   39685   1813
17073   39563   1771
17547   39421   1709
18021   39290   1644
18495   39170   1604
18970   39074   1589
19444   38989   1550
19918   38920   1560
20392   38851   1571
20867   38780   1550
21341   38720   1559
21815   38662   1551
22289   38609   1575
22764   38557   1578
23238   38502   1583
23712   38452   1575
24186   38404   1596
24661   38356   1600
25135   38319   1625
25609   38271   1609
26083   38234   1625
26558   38186   1625
27032   38153   1650
27506   38121   1650
27980   38079   1650
28455   38047   1675
28929   38015   1675
29403   37984   1675
29877   37952   1697
30352   37921   1700
30826   37889   1676
31300   37857   1700
31774   37825   1700
32248   37793   1700
32723   37752   1685
33197   37710   1675
33671   37673   1700
34145   37627   1704
34620   37595   1725
35094   37554   1725
35568   37522   1747
36042   37476   1787
36517   37418   1800
36991   37353   1817
37465   37292   1831
37939   37245   1871
38414   37174   1885
38888   37090   1900
39362   37023   1925
39836   36998   1958
40311   36983   2018
40785   36957   2041
41259   36941   2097
41733   36916   2162
42208   36866   2256
42682   36714   2366
43156   36354   2472
43630   35840   2650
44105   35152   2943
44579   34223   3399
45053   33330   3975
45527   33330   3975
46002   33330   3975
46476   33330   3975
46950   33330   3975
>;
battery0_profile_t3_num = <100>;
battery0_profile_t3_col = <3>;
battery0_profile_t3 =
<
0       43160   3150
474     42932   3252
948     42785   3379
1423    42651   3456
1897    42521   3525
2371    42395   3548
2845    42269   3563
3320    42152   3600
3794    42026   3600
4268    41909   3625
4742    41791   3646
5217    41668   3650
5691    41547   3651
6165    41437   3675
6639    41326   3655
7114    41215   3675
7588    41105   3716
8062    40992   3700
8536    40881   3714
9011    40781   3722
9485    40670   3754
9959    40569   3825
10433   40459   3781
10908   40358   3789
11382   40256   3825
11856   40154   3825
12330   40056   3825
12805   39961   3845
13279   39862   3840
13753   39761   3825
14227   39661   3850
14702   39546   3821
15176   39420   3781
15650   39283   3717
16124   39157   3654
16598   39050   3638
17073   38956   3625
17547   38877   3641
18021   38806   3675
18495   38736   3675
18970   38673   3700
19444   38610   3700
19918   38556   3740
20392   38495   3754
20867   38447   3775
21341   38399   3825
21815   38351   3849
22289   38299   3877
22764   38257   3903
23238   38209   3925
23712   38172   3957
24186   38123   3997
24661   38091   4037
25135   38059   4075
25609   38017   4107
26083   37986   4130
26558   37954   4170
27032   37923   4209
27506   37890   4225
27980   37869   4264
28455   37849   4307
28929   37825   4350
29403   37804   4408
29877   37772   4447
30352   37751   4537
30826   37718   4604
31300   37687   4700
31774   37645   4762
32248   37605   4841
32723   37562   4956
33197   37510   5049
33671   37467   5193
34145   37404   5318
34620   37349   5477
35094   37283   5626
35568   37213   5791
36042   37140   5964
36517   37056   6138
36991   36992   6379
37465   36941   6643
37939   36903   6923
38414   36871   7261
38888   36839   7683
39362   36792   8218
39836   36715   8889
40311   36555   9692
40785   36264   10658
41259   35821   11990
41733   35195   14328
42208   34350   17484
42682   33770   19475
43156   33770   19475
43630   33770   19475
44105   33770   19475
44579   33770   19475
45053   33770   19475
45527   33770   19475
46002   33770   19475
46476   33770   19475
46950   33770   19475
>;
battery0_profile_t4_num = <100>;
battery0_profile_t4_col = <3>;
battery0_profile_t4 =
<
0       42820   4925
474     42510   5085
948     42181   5548
1423    41919   6185
1897    41721   6596
2371    41556   6912
2845    41413   7051
3320    41282   7127
3794    41156   7184
4268    41029   7232
4742    40903   7292
5217    40784   7361
5691    40657   7401
6165    40524   7440
6639    40392   7470
7114    40258   7469
7588    40121   7459
8062    39992   7426
8536    39866   7464
9011    39741   7453
9485    39623   7457
9959    39509   7475
10433   39399   7475
10908   39302   7475
11382   39206   7521
11856   39121   7524
12330   39038   7581
12805   38959   7620
13279   38884   7660
13753   38821   7699
14227   38748   7728
14702   38683   7784
15176   38620   7844
15650   38557   7883
16124   38493   7923
16598   38440   8000
17073   38387   8050
17547   38330   8066
18021   38279   8118
18495   38224   8164
18970   38177   8222
19444   38130   8276
19918   38092   8360
20392   38045   8400
20867   38005   8457
21341   37963   8534
21815   37931   8598
22289   37899   8702
22764   37868   8808
23238   37829   8910
23712   37792   9052
24186   37752   9236
24661   37711   9409
25135   37669   9581
25609   37615   9779
26083   37564   10007
26558   37508   10244
27032   37455   10472
27506   37381   10649
27980   37317   10871
28455   37254   11126
28929   37191   11366
29403   37131   11687
29877   37074   11981
30352   37026   12322
30826   36977   12599
31300   36920   13050
31774   36860   13431
32248   36780   13786
32723   36653   14163
33197   36481   14523
33671   36222   14878
34145   35831   15205
34620   35256   15756
35094   34414   16694
35568   33970   17200
36042   33970   17200
36517   33970   17200
36991   33970   17200
37465   33970   17200
37939   33970   17200
38414   33970   17200
38888   33970   17200
39362   33970   17200
39836   33970   17200
40311   33970   17200
40785   33970   17200
41259   33970   17200
41733   33970   17200
42208   33970   17200
42682   33970   17200
43156   33970   17200
43630   33970   17200
44105   33970   17200
44579   33970   17200
45053   33970   17200
45527   33970   17200
46002   33970   17200
46476   33970   17200
46950   33970   17200
>;
battery0_profile_t5_num = <100>;
battery0_profile_t5_col = <3>;
battery0_profile_t5 =
<
0       41440   10350
474     41121   10757
948     40854   11403
1423    40601   11861
1897    40343   12239
2371    40081   12541
2845    39827   13196
3320    39587   13974
3794    39388   14612
4268    39227   15008
4742    39093   15184
5217    38968   15323
5691    38867   15400
6165    38769   15446
6639    38678   15515
7114    38591   15594
7588    38512   15668
8062    38431   15700
8536    38352   15789
9011    38273   15878
9485    38201   15936
9959    38135   16068
10433   38065   16116
10908   38002   16246
11382   37936   16355
11856   37864   16474
12330   37791   16598
12805   37719   16736
13279   37640   16865
13753   37551   17023
14227   37467   17231
14702   37380   17471
15176   37285   17763
15650   37177   18042
16124   37066   18381
16598   36960   18724
17073   36834   19044
17547   36694   19373
18021   36512   19566
18495   36257   19781
18970   35857   19929
19444   35242   20255
19918   34210   20367
20392   33770   19450
20867   33770   19450
21341   33770   19450
21815   33770   19450
22289   33770   19450
22764   33770   19450
23238   33770   19450
23712   33770   19450
24186   33770   19450
24661   33770   19450
25135   33770   19450
25609   33770   19450
26083   33770   19450
26558   33770   19450
27032   33770   19450
27506   33770   19450
27980   33770   19450
28455   33770   19450
28929   33770   19450
29403   33770   19450
29877   33770   19450
30352   33770   19450
30826   33770   19450
31300   33770   19450
31774   33770   19450
32248   33770   19450
32723   33770   19450
33197   33770   19450
33671   33770   19450
34145   33770   19450
34620   33770   19450
35094   33770   19450
35568   33770   19450
36042   33770   19450
36517   33770   19450
36991   33770   19450
37465   33770   19450
37939   33770   19450
38414   33770   19450
38888   33770   19450
39362   33770   19450
39836   33770   19450
40311   33770   19450
40785   33770   19450
41259   33770   19450
41733   33770   19450
42208   33770   19450
42682   33770   19450
43156   33770   19450
43630   33770   19450
44105   33770   19450
44579   33770   19450
45053   33770   19450
45527   33770   19450
46002   33770   19450
46476   33770   19450
46950   33770   19450
>;
battery1_profile_t0_num = <100>;
battery1_profile_t0_col = <3>;
battery1_profile_t0 =
<
0       44010   600
475     43889   600
951     43778   621
1426    43667   600
1902    43566   625
2377    43455   625
2853    43354   625
3328    43243   625
3804    43132   625
4279    43019   618
4755    42901   621
5230    42785   614
5705    42669   625
6181    42558   640
6656    42437   630
7132    42318   631
7607    42205   634
8083    42085   626
8558    41968   637
9034    41852   650
9509    41739   650
9985    41625   650
10460   41507   650
10935   41396   650
11411   41285   650
11886   41174   650
12362   41073   669
12837   40962   650
13313   40861   665
13788   40760   675
14264   40655   664
14739   40559   675
15215   40455   675
15690   40360   675
16165   40274   698
16641   40180   700
17116   40086   702
17592   40000   708
18067   39917   731
18543   39829   729
19018   39744   750
19494   39649   750
19969   39500   710
20445   39334   645
20920   39206   625
21395   39119   641
21871   39033   625
22346   38964   637
22822   38896   625
23297   38832   625
23773   38769   625
24248   38714   625
24724   38657   636
25199   38599   625
25675   38552   640
26150   38502   645
26625   38446   625
27101   38405   641
27576   38360   650
28052   38313   650
28527   38275   650
29003   38228   650
29478   38193   658
29954   38153   652
30429   38120   662
30905   38078   650
31380   38053   683
31855   38015   675
32331   37983   675
32806   37947   689
33282   37890   650
33757   37810   625
34233   37723   625
34708   37667   644
35184   37616   641
35659   37571   648
36135   37519   637
36610   37467   625
37085   37419   625
37561   37382   625
38036   37343   625
38512   37301   636
38987   37249   625
39463   37186   625
39938   37114   625
40414   37059   625
40889   37002   641
41365   36913   625
41840   36849   612
42315   36839   625
42791   36823   625
43266   36810   632
43742   36801   650
44217   36771   636
44693   36715   674
45168   36478   650
45644   36064   675
46119   35523   675
46595   34773   685
47070   33690   750
>;
battery1_profile_t1_num = <100>;
battery1_profile_t1_col = <3>;
battery1_profile_t1 =
<
0       43900   800
475     43785   829
951     43680   829
1426    43577   850
1902    43476   850
2377    43365   850
2853    43264   875
3328    43152   873
3804    43032   850
4279    42922   850
4755    42802   829
5230    42690   875
5705    42569   875
6181    42452   850
6656    42335   870
7132    42216   869
7607    42095   875
8083    41984   875
8558    41863   863
9034    41752   897
9509    41632   875
9985    41518   875
10460   41407   875
10935   41296   900
11411   41186   877
11886   41084   900
12362   40976   906
12837   40872   904
13313   40771   925
13788   40670   925
14264   40569   925
14739   40470   929
15215   40375   950
15690   40280   967
16165   40194   973
16641   40100   975
17116   40015   1000
17592   39920   1000
18067   39835   1025
18543   39739   1025
19018   39636   1039
19494   39499   974
19969   39330   910
20445   39199   855
20920   39104   856
21395   39022   850
21871   38953   850
22346   38879   837
22822   38816   847
23297   38759   842
23773   38699   843
24248   38644   847
24724   38592   839
25199   38539   826
25675   38492   835
26150   38444   845
26625   38396   845
27101   38359   850
27576   38310   850
28052   38273   861
28527   38235   875
29003   38195   875
29478   38163   875
29954   38132   898
30429   38095   875
30905   38068   898
31380   38037   875
31855   38005   900
32331   37973   879
32806   37942   900
33282   37900   875
33757   37836   850
34233   37786   850
34708   37747   850
35184   37700   850
35659   37652   850
36135   37605   837
36610   37558   848
37085   37526   842
37561   37492   850
38036   37453   871
38512   37402   839
38987   37339   826
39463   37282   865
39938   37224   850
40414   37169   850
40889   37088   841
41365   37003   825
41840   36975   825
42315   36960   828
42791   36953   850
43266   36937   875
43742   36921   897
44217   36882   900
44693   36772   898
45168   36417   881
45644   35907   925
46119   35238   946
46595   34289   1052
47070   33850   1125
>;
battery1_profile_t2_num = <100>;
battery1_profile_t2_col = <3>;
battery1_profile_t2 =
<
0       43740   1325
475     43603   1354
951     43478   1375
1426    43375   1413
1902    43256   1400
2377    43145   1423
2853    43029   1425
3328    42913   1427
3804    42796   1433
4279    42672   1432
4755    42552   1429
5230    42435   1450
5705    42319   1450
6181    42198   1450
6656    42077   1455
7132    41966   1456
7607    41845   1459
8083    41734   1475
8558    41613   1475
9034    41502   1475
9509    41389   1475
9985    41278   1500
10460   41167   1500
10935   41056   1500
11411   40955   1525
11886   40851   1525
12362   40746   1531
12837   40642   1529
13313   40545   1560
13788   40450   1575
14264   40355   1589
14739   40260   1600
15215   40165   1619
15690   40073   1633
16165   39985   1650
16641   39890   1650
17116   39804   1675
17592   39693   1675
18067   39564   1637
18543   39406   1558
19018   39256   1464
19494   39149   1450
19969   39060   1450
20445   38981   1450
20920   38902   1431
21395   38836   1434
21871   38773   1450
22346   38714   1438
22822   38656   1447
23297   38599   1442
23773   38549   1468
24248   38494   1450
24724   38447   1475
25199   38399   1475
25675   38352   1475
26150   38314   1500
26625   38274   1500
27101   38233   1500
27576   38190   1500
28052   38159   1525
28527   38117   1521
29003   38085   1519
29478   38053   1525
29954   38022   1525
30429   38000   1562
30905   37968   1552
31380   37937   1558
31855   37905   1550
32331   37882   1571
32806   37842   1550
33282   37810   1575
33757   37768   1550
34233   37715   1525
34708   37675   1544
35184   37630   1550
35659   37591   1550
36135   37555   1562
36610   37517   1550
37085   37469   1567
37561   37419   1575
38036   37356   1596
38512   37292   1575
38987   37239   1600
39463   37170   1600
39938   37080   1600
40414   37024   1600
40889   36996   1600
41365   36981   1600
41840   36965   1638
42315   36948   1675
42791   36916   1693
43266   36857   1732
43742   36643   1772
44217   36199   1798
44693   35610   1853
45168   34796   2003
45644   33780   2250
46119   33780   2250
46595   33780   2250
47070   33780   2250
>;
battery1_profile_t3_num = <100>;
battery1_profile_t3_col = <3>;
battery1_profile_t3 =
<
0       43420   2275
475     43247   2333
951     43106   2404
1426    42980   2444
1902    42853   2475
2377    42735   2498
2853    42609   2513
3328    42492   2525
3804    42366   2525
4279    42242   2550
4755    42122   2550
5230    42005   2575
5705    41889   2600
6181    41772   2585
6656    41655   2575
7132    41536   2594
7607    41425   2625
8083    41314   2625
8558    41203   2650
9034    41092   2650
9509    40986   2668
9985    40878   2675
10460   40776   2698
10935   40671   2687
11411   40575   2725
11886   40471   2725
12362   40373   2744
12837   40279   2766
13313   40185   2800
13788   40090   2800
14264   39995   2825
14739   39900   2850
15215   39798   2850
15690   39693   2867
16165   39557   2827
16641   39400   2737
17116   39263   2698
17592   39143   2658
18067   39047   2656
18543   38959   2654
19018   38889   2650
19494   38820   2650
19969   38756   2675
20445   38695   2680
20920   38639   2700
21395   38579   2700
21871   38532   2723
22346   38474   2713
22822   38427   2750
23297   38379   2750
23773   38332   2775
24248   38284   2797
24724   38247   2811
25199   38199   2826
25675   38162   2850
26150   38126   2880
26625   38094   2900
27101   38056   2909
27576   38020   2925
28052   37999   2950
28527   37967   2975
29003   37943   2994
29478   37913   3000
29954   37891   3023
30429   37860   3013
30905   37838   3050
31380   37813   3067
31855   37785   3075
32331   37745   3075
32806   37707   3075
33282   37660   3100
33757   37618   3115
34233   37585   3154
34708   37545   3175
35184   37496   3200
35659   37433   3223
36135   37369   3263
36610   37307   3303
37085   37246   3342
37561   37177   3407
38036   37080   3446
38512   37007   3508
38987   36970   3626
39463   36938   3721
39938   36916   3894
40414   36884   4092
40889   36839   4357
41365   36782   4785
41840   36589   5312
42315   36179   6114
42791   35582   7654
43266   34776   11769
43742   33790   19550
44217   33790   19550
44693   33790   19550
45168   33790   19550
45644   33790   19550
46119   33790   19550
46595   33790   19550
47070   33790   19550
>;
battery1_profile_t4_num = <100>;
battery1_profile_t4_col = <3>;
battery1_profile_t4 =
<
0       42760   4900
475     42510   5017
951     42345   5238
1426    42202   5319
1902    42063   5383
2377    41936   5423
2853    41809   5463
3328    41692   5500
3804    41566   5517
4279    41452   5538
4755    41332   5554
5230    41220   5575
5705    41109   5600
6181    40998   5625
6656    40887   5675
7132    40776   5675
7607    40669   5709
8083    40564   5725
8558    40458   5726
9034    40353   5728
9509    40249   5750
9985    40151   5783
10460   40056   5800
10935   39951   5800
11411   39855   5825
11886   39738   5809
12362   39621   5794
12837   39486   5734
13313   39357   5690
13788   39230   5675
14264   39119   5661
14739   39020   5654
15215   38933   5675
15690   38853   5692
16165   38783   5725
16641   38710   5725
17116   38647   5752
17592   38593   5775
18067   38532   5806
18543   38476   5825
19018   38427   5871
19494   38380   5876
19969   38332   5925
20445   38285   5930
20920   38245   5969
21395   38199   5984
21871   38161   6047
22346   38120   6076
22822   38087   6100
23297   38046   6117
23773   38014   6182
24248   37991   6222
24724   37961   6261
25199   37930   6301
25675   37914   6356
26150   37888   6385
26625   37872   6445
27101   37846   6484
27576   37830   6549
28052   37809   6614
28527   37787   6679
29003   37755   6737
29478   37713   6800
29954   37673   6873
30429   37635   6987
30905   37588   7104
31380   37540   7217
31855   37480   7344
32331   37417   7505
32806   37353   7703
33282   37280   7876
33757   37216   8128
34233   37139   8401
34708   37044   8696
35184   36966   9028
35659   36912   9454
36135   36875   9942
36610   36837   10570
37085   36796   11369
37561   36752   12493
38036   36687   14154
38512   36544   17316
38987   36223   24383
39463   35704   24407
39938   34945   22663
40414   33980   20150
40889   33980   20150
41365   33980   20150
41840   33980   20150
42315   33980   20150
42791   33980   20150
43266   33980   20150
43742   33980   20150
44217   33980   20150
44693   33980   20150
45168   33980   20150
45644   33980   20150
46119   33980   20150
46595   33980   20150
47070   33980   20150
>;
battery1_profile_t5_num = <100>;
battery1_profile_t5_col = <3>;
battery1_profile_t5 =
<
0       41490   8600
475     41125   8907
951     40891   9488
1426    40725   9807
1902    40569   9984
2377    40436   10142
2853    40299   10250
3328    40173   10357
3804    40056   10442
4279    39939   10532
4755    39821   10592
5230    39705   10636
5705    39589   10700
6181    39462   10740
6656    39345   10780
7132    39218   10781
7607    39095   10793
8083    38984   10801
8558    38888   10863
9034    38794   10903
9509    38713   10925
9985    38644   10975
10460   38574   11020
10935   38521   11087
11411   38458   11103
11886   38404   11150
12362   38353   11231
12837   38305   11291
13313   38258   11335
13788   38210   11375
14264   38178   11468
14739   38137   11537
15215   38105   11619
15690   38073   11692
16165   38042   11771
16641   38020   11850
17116   37989   11932
17592   37973   12050
18067   37947   12132
18543   37923   12309
19018   37901   12421
19494   37880   12526
19969   37854   12660
20445   37828   12718
20920   37805   12858
21395   37773   13010
21871   37741   13169
22346   37710   13365
22822   37668   13541
23297   37629   13761
23773   37582   13991
24248   37534   14251
24724   37477   14539
25199   37419   14807
25675   37355   15148
26150   37292   15500
26625   37221   15877
27101   37142   16277
27576   37061   16746
28052   36997   17286
28527   36935   17896
29003   36895   18665
29478   36853   19670
29954   36813   20973
30429   36765   23070
30905   36708   26509
31380   36624   26590
31855   36420   26148
32331   33990   20000
32806   33990   20000
33282   33990   20000
33757   33990   20000
34233   33990   20000
34708   33990   20000
35184   33990   20000
35659   33990   20000
36135   33990   20000
36610   33990   20000
37085   33990   20000
37561   33990   20000
38036   33990   20000
38512   33990   20000
38987   33990   20000
39463   33990   20000
39938   33990   20000
40414   33990   20000
40889   33990   20000
41365   33990   20000
41840   33990   20000
42315   33990   20000
42791   33990   20000
43266   33990   20000
43742   33990   20000
44217   33990   20000
44693   33990   20000
45168   33990   20000
45644   33990   20000
46119   33990   20000
46595   33990   20000
47070   33990   20000
>;
battery2_profile_t0_num = <100>;
battery2_profile_t0_col = <3>;
battery2_profile_t0 =
<
0       44200   550
500     44060   550
999     43937   558
1499    43820   550
1999    43710   567
2498    43600   558
2998    43490   550
3498    43384   575
3998    43270   558
4497    43161   575
4997    43044   575
5497    42927   575
5996    42811   575
6496    42694   591
6996    42568   575
7495    42451   600
7995    42328   575
8495    42208   575
8995    42091   600
9494    41966   583
9994    41846   575
10494   41729   600
10993   41613   592
11493   41496   600
11993   41379   600
12492   41273   600
12992   41160   600
13492   41050   600
13992   40940   600
14491   40830   600
14991   40730   625
15491   40630   617
15990   40527   625
16490   40430   625
16990   40330   642
17489   40233   633
17989   40140   650
18489   40050   658
18988   39960   667
19488   39870   675
19988   39787   691
20488   39694   700
20987   39601   700
21487   39454   659
21987   39291   600
22486   39161   600
22986   39067   591
23486   38987   583
23985   38921   600
24485   38850   583
24985   38787   575
25485   38731   600
25984   38671   591
26484   38611   583
26984   38561   600
27483   38500   575
27983   38450   575
28483   38410   600
28982   38360   600
29482   38313   600
29982   38270   575
30482   38230   600
30981   38190   600
31481   38150   600
31981   38117   625
32480   38083   625
32980   38050   625
33480   38017   625
33979   37983   625
34479   37950   650
34979   37910   633
35478   37834   600
35978   37740   575
36478   37674   575
36978   37620   575
37477   37570   575
37977   37530   600
38477   37480   600
38976   37430   575
39476   37390   584
39976   37350   592
40475   37310   600
40975   37260   591
41475   37197   583
41975   37131   600
42474   37064   575
42974   37004   592
43474   36921   575
43973   36857   566
44473   36840   575
44973   36830   575
45472   36820   592
45972   36807   609
46472   36780   625
46972   36703   633
47471   36442   608
47971   36009   650
48471   35429   675
48970   34626   700
49470   33410   800
>;
battery2_profile_t1_num = <100>;
battery2_profile_t1_col = <3>;
battery2_profile_t1 =
<
0       44110   750
500     43983   750
999     43877   767
1499    43770   775
1999    43670   775
2498    43560   758
2998    43460   775
3498    43344   759
3998    43237   775
4497    43121   750
4997    43004   766
5497    42887   758
5996    42771   775
6496    42648   784
6996    42528   775
7495    42401   775
7995    42284   775
8495    42165   775
8995    42041   800
9494    41922   800
9994    41806   800
10494   41689   800
10993   41573   817
11493   41456   800
11993   41339   825
12492   41230   817
12992   41116   816
13492   41010   825
13992   40900   817
14491   40790   808
14991   40690   850
15491   40590   850
15990   40490   850
16490   40390   850
16990   40290   858
17489   40200   875
17989   40110   900
18489   40017   892
18988   39924   908
19488   39840   925
19988   39750   934
20488   39650   950
20987   39541   950
21487   39384   859
21987   39234   800
22486   39111   775
22986   39017   750
23486   38937   750
23985   38871   750
24485   38804   750
24985   38741   733
25485   38691   750
25984   38631   750
26484   38574   733
26984   38521   750
27483   38480   750
27983   38430   750
28483   38380   750
28982   38340   758
29482   38300   775
29982   38260   775
30482   38220   783
30981   38183   775
31481   38150   775
31981   38117   800
32480   38083   775
32980   38050   775
33480   38023   792
33979   37993   800
34479   37960   800
34979   37927   800
35478   37880   775
35978   37830   775
36478   37780   759
36978   37733   750
37477   37690   750
37977   37650   775
38477   37600   750
38976   37560   750
39476   37517   750
39976   37484   758
40475   37450   775
40975   37394   759
41475   37327   750
41975   37271   775
42474   37211   766
42974   37147   758
43474   37061   775
43973   36997   750
44473   36977   775
44973   36960   751
45472   36953   775
45972   36937   784
46472   36910   800
46972   36846   800
47471   36632   800
47971   36199   825
48471   35599   842
48970   34803   942
49470   33600   1100
>;
battery2_profile_t2_num = <100>;
battery2_profile_t2_col = <3>;
battery2_profile_t2 =
<
0       43940   1225
500     43803   1258
999     43690   1308
1499    43580   1325
1999    43474   1325
2498    43367   1342
2998    43250   1350
3498    43134   1350
3998    43017   1350
4497    42901   1350
4997    42784   1350
5497    42657   1350
5996    42541   1375
6496    42414   1366
6996    42288   1350
7495    42171   1375
7995    42048   1359
8495    41928   1375
8995    41811   1375
9494    41682   1367
9994    41569   1384
10494   41459   1400
10993   41343   1400
11493   41229   1409
11993   41119   1400
12492   41010   1417
12992   40900   1425
13492   40800   1450
13992   40690   1442
14491   40590   1450
14991   40490   1475
15491   40390   1475
15990   40290   1500
16490   40190   1500
16990   40100   1508
17489   40010   1542
17989   39920   1550
18489   39820   1550
18988   39720   1558
19488   39610   1550
19988   39464   1492
20488   39304   1400
20987   39171   1350
21487   39071   1350
21987   38984   1342
22486   38910   1325
22986   38834   1300
23486   38777   1342
23985   38711   1325
24485   38650   1325
24985   38597   1342
25485   38541   1325
25984   38491   1350
26484   38441   1350
26984   38391   1350
27483   38347   1367
27983   38300   1375
28483   38260   1375
28982   38217   1375
29482   38183   1409
29982   38140   1400
30482   38107   1400
30981   38073   1425
31481   38050   1450
31981   38017   1433
32480   37983   1450
32980   37960   1450
33480   37927   1450
33979   37897   1450
34479   37870   1475
34979   37837   1450
35478   37803   1450
35978   37760   1425
36478   37720   1450
36978   37670   1450
37477   37620   1425
37977   37587   1434
38477   37554   1450
38976   37520   1475
39476   37470   1475
39976   37407   1475
40475   37341   1475
40975   37280   1475
41475   37227   1500
41975   37151   1500
42474   37058   1500
42974   37017   1508
43474   36990   1501
43973   36977   1534
44473   36957   1550
44973   36940   1574
45472   36900   1617
45972   36796   1650
46472   36478   1675
46972   35945   1750
47471   35248   1917
47971   34247   2201
48471   33320   2600
48970   33320   2600
49470   33320   2600
>;
battery2_profile_t3_num = <100>;
battery2_profile_t3_col = <3>;
battery2_profile_t3 =
<
0       43640   2150
500     43460   2200
999     43327   2292
1499    43200   2325
1999    43084   2375
2498    42964   2400
2998    42840   2400
3498    42714   2416
3998    42594   2425
4497    42471   2425
4997    42344   2425
5497    42217   2433
5996    42101   2450
6496    41974   2441
6996    41858   2450
7495    41741   2475
7995    41618   2475
8495    41498   2458
8995    41381   2475
9494    41272   2500
9994    41156   2500
10494   41039   2500
10993   40933   2525
11493   40829   2550
11993   40719   2550
12492   40620   2567
12992   40510   2575
13492   40410   2600
13992   40310   2592
14491   40213   2608
14991   40120   2650
15491   40020   2650
15990   39923   2683
16490   39830   2700
16990   39730   2717
17489   39607   2700
17989   39470   2650
18489   39314   2550
18988   39177   2492
19488   39070   2475
19988   38977   2475
20488   38897   2475
20987   38830   2475
21487   38764   2500
21987   38697   2500
22486   38640   2500
22986   38580   2541
23486   38520   2525
23985   38470   2550
24485   38420   2566
24985   38371   2575
25485   38321   2600
25984   38281   2600
26484   38234   2633
26984   38191   2626
27483   38157   2667
27983   38120   2684
28483   38080   2700
28982   38047   2725
29482   38013   2759
29982   37980   2775
30482   37957   2800
30981   37927   2817
31481   37900   2850
31981   37883   2875
32480   37857   2900
32980   37830   2900
33480   37807   2925
33979   37783   2950
34479   37750   2950
34979   37707   2967
35478   37660   2958
35978   37620   3000
36478   37577   3016
36978   37530   3050
37477   37480   3075
37977   37424   3125
38477   37357   3183
38976   37290   3225
39476   37234   3283
39976   37151   3333
40475   37051   3375
40975   36990   3491
41475   36954   3599
41975   36920   3748
42474   36894   3963
42974   36854   4245
43474   36811   4694
43973   36715   5413
44473   36449   6585
44973   35948   8934
45472   35235   18289
45972   34258   20859
46472   33940   19900
46972   33940   19900
47471   33940   19900
47971   33940   19900
48471   33940   19900
48970   33940   19900
49470   33940   19900
>;
battery2_profile_t4_num = <100>;
battery2_profile_t4_col = <3>;
battery2_profile_t4 =
<
0       43070   4050
500     42803   4200
999     42630   4458
1499    42480   4575
1999    42347   4633
2498    42214   4683
2998    42090   4725
3498    41964   4766
3998    41837   4808
4497    41711   4825
4997    41594   4850
5497    41477   4883
5996    41361   4925
6496    41244   4925
6996    41128   4933
7495    41011   4950
7995    40904   4975
8495    40791   5033
8995    40681   5050
9494    40579   5067
9994    40469   5084
10494   40369   5150
10993   40263   5150
11493   40169   5184
11993   40069   5225
12492   39970   5250
12992   39866   5291
13492   39760   5300
13992   39636   5283
14491   39503   5250
14991   39370   5225
15491   39227   5175
15990   39107   5175
16490   39010   5175
16990   38917   5175
17489   38837   5225
17989   38770   5250
18489   38693   5267
18988   38637   5325
19488   38570   5325
19988   38514   5375
20488   38460   5416
20987   38410   5475
21487   38360   5509
21987   38310   5533
22486   38270   5599
22986   38220   5625
23486   38184   5683
23985   38140   5725
24485   38100   5766
24985   38064   5816
25485   38030   5875
25984   38004   5932
26484   37967   5966
26984   37940   6000
27483   37923   6067
27983   37897   6117
28483   37880   6175
28982   37857   6217
29482   37837   6284
29982   37820   6350
30482   37797   6400
30981   37773   6458
31481   37740   6525
31981   37707   6625
32480   37660   6692
32980   37620   6800
33480   37570   6925
33979   37517   7075
34479   37460   7250
34979   37383   7408
35478   37317   7608
35978   37250   7849
36478   37174   8107
36978   37080   8390
37477   36990   8773
37977   36927   9213
38477   36884   9754
38976   36840   10470
39476   36807   11524
39976   36760   13090
40475   36701   15920
40975   36594   24359
41475   36298   25892
41975   35667   24273
42474   34269   20879
42974   33990   21050
43474   33990   21050
43973   33990   21050
44473   33990   21050
44973   33990   21050
45472   33990   21050
45972   33990   21050
46472   33990   21050
46972   33990   21050
47471   33990   21050
47971   33990   21050
48471   33990   21050
48970   33990   21050
49470   33990   21050
>;
battery2_profile_t5_num = <100>;
battery2_profile_t5_col = <3>;
battery2_profile_t5 =
<
0       42420   6600
500     42064   6850
999     41800   7441
1499    41610   7775
1999    41467   7850
2498    41334   7908
2998    41210   8025
3498    41077   8066
3998    40957   8116
4497    40841   8175
4997    40724   8184
5497    40617   8250
5996    40501   8299
6496    40391   8383
6996    40278   8416
7495    40161   8524
7995    40054   8616
8495    39941   8616
8995    39831   8625
9494    39712   8575
9994    39582   8600
10494   39449   8576
10993   39326   8625
11493   39199   8625
11993   39089   8625
12492   38990   8675
12992   38903   8801
13492   38830   8975
13992   38753   8967
14491   38687   9000
14991   38620   9025
15491   38560   9050
15990   38500   9075
16490   38450   9125
16990   38393   9108
17489   38340   9192
17989   38300   9275
18489   38250   9342
18988   38203   9391
19488   38160   9425
19988   38127   9458
20488   38093   9541
20987   38050   9575
21487   38027   9641
21987   37997   9699
22486   37970   9799
22986   37947   9833
23486   37927   9916
23985   37900   9975
24485   37883   10083
24985   37857   10174
25485   37830   10274
25984   37807   10357
26484   37784   10498
26984   37750   10623
27483   37717   10792
27983   37673   10943
28483   37630   11151
28982   37580   11351
29482   37530   11601
29982   37470   11851
30482   37413   12076
30981   37347   12367
31481   37280   12701
31981   37207   13034
32480   37130   13425
32980   37040   13825
33480   36973   14341
33979   36930   14933
34479   36890   15674
34979   36857   16755
35478   36810   18327
35978   36760   21063
36478   36668   26400
36978   36481   26278
37477   36036   25327
37977   35239   23774
38477   33980   20400
38976   33980   20400
39476   33980   20400
39976   33980   20400
40475   33980   20400
40975   33980   20400
41475   33980   20400
41975   33980   20400
42474   33980   20400
42974   33980   20400
43474   33980   20400
43973   33980   20400
44473   33980   20400
44973   33980   20400
45472   33980   20400
45972   33980   20400
46472   33980   20400
46972   33980   20400
47471   33980   20400
47971   33980   20400
48471   33980   20400
48970   33980   20400
49470   33980   20400
>;
battery3_profile_t0_num = <100>;
battery3_profile_t0_col = <3>;
battery3_profile_t0 =
<
0       44200   550
492     44032   566
985     43887   575
1477    43765   598
1970    43638   575
2462    43523   600
2955    43408   578
3447    43293   600
3939    43178   600
4432    43064   600
4924    42943   613
5417    42820   600
5909    42697   600
6402    42578   600
6894    42456   600
7386    42332   600
7879    42206   600
8371    42090   625
8864    41965   600
9356    41850   625
9848    41726   602
10341   41610   614
10833   41495   625
11326   41378   625
11818   41263   625
12311   41150   604
12803   41043   645
13295   40928   625
13788   40824   625
14280   40719   643
14773   40615   635
15265   40517   650
15758   40418   667
16250   40317   667
16742   40221   674
17235   40129   681
17727   40034   675
18220   39943   675
18712   39856   686
19205   39769   700
19697   39687   721
20189   39595   712
20682   39499   718
21174   39357   655
21667   39204   600
22159   39084   623
22652   38993   600
23144   38915   609
23636   38839   601
24129   38773   608
24621   38710   600
25114   38651   600
25606   38595   609
26098   38542   600
26591   38493   623
27083   38444   625
27576   38393   625
28068   38344   625
28561   38300   613
29053   38256   625
29545   38214   625
30038   38171   611
30530   38139   627
31023   38098   631
31515   38062   635
32008   38029   625
32500   37997   642
32992   37967   658
33485   37941   675
33977   37908   660
34470   37869   662
34962   37786   602
35455   37703   600
35947   37634   605
36439   37585   604
36932   37535   600
37424   37487   604
37917   37446   625
38409   37401   625
38902   37359   625
39394   37326   625
39886   37289   625
40379   37239   624
40871   37180   617
41364   37118   625
41856   37061   625
42348   36996   615
42841   36918   625
43333   36854   625
43826   36834   614
44318   36828   625
44811   36812   625
45303   36795   650
45795   36765   672
46288   36677   650
46780   36418   650
47273   35987   654
47765   35427   700
48258   34656   718
48750   33520   800
>;
battery3_profile_t1_num = <100>;
battery3_profile_t1_col = <3>;
battery3_profile_t1 =
<
0       44090   750
492     43939   766
985     43820   782
1477    43705   800
1970    43594   815
2462    43483   800
2955    43368   800
3447    43253   788
3939    43138   779
4432    43024   800
4924    42898   787
5417    42780   822
5909    42657   819
6402    42532   800
6894    42407   800
7386    42285   800
7879    42163   800
8371    42040   800
8864    41925   825
9356    41800   800
9848    41685   800
10341   41570   825
10833   41455   825
11326   41338   825
11818   41223   825
12311   41110   829
12803   41003   850
13295   40898   850
13788   40784   850
14280   40686   868
14773   40585   875
15265   40486   875
15758   40378   875
16250   40280   892
16742   40182   875
17235   40089   890
17727   39997   907
18220   39904   902
18712   39821   939
19205   39739   950
19697   39649   929
20189   39560   950
20682   39459   968
21174   39317   885
21667   39174   839
22159   39054   775
22652   38963   775
23144   38881   775
23636   38809   775
24129   38743   775
24621   38680   775
25114   38621   775
25606   38571   775
26098   38522   800
26591   38473   777
27083   38424   786
27576   38373   775
28068   38333   775
28561   38290   788
29053   38247   800
29545   38214   800
30038   38171   800
30530   38139   802
31023   38105   806
31515   38072   800
32008   38049   825
32500   38017   825
32992   37984   825
33485   37961   849
33977   37928   825
34470   37905   850
34962   37863   805
35455   37808   786
35947   37756   780
36439   37715   779
36932   37675   788
37424   37636   796
37917   37586   775
38409   37546   786
38902   37509   777
39394   37486   800
39886   37443   784
40379   37399   775
40871   37333   775
41364   37278   792
41856   37221   799
42348   37166   800
42841   37086   794
43333   37005   775
43826   36974   789
44318   36968   820
44811   36952   800
45303   36935   825
45795   36906   825
46288   36850   825
46780   36661   835
47273   36267   852
47765   35722   911
48258   35010   984
48750   33980   1075
>;
battery3_profile_t2_num = <100>;
battery3_profile_t2_col = <3>;
battery3_profile_t2 =
<
0       43870   1275
492     43699   1323
985     43570   1382
1477    43455   1423
1970    43332   1400
2462    43213   1406
2955    43098   1447
3447    42973   1425
3939    42857   1446
4432    42734   1445
4924    42608   1425
5417    42481   1428
5909    42359   1431
6402    42232   1425
6894    42116   1450
7386    41992   1450
7879    41873   1450
8371    41750   1450
8864    41635   1475
9356    41513   1457
9848    41396   1475
10341   41290   1486
10833   41175   1500
11326   41067   1500
11818   40953   1500
12311   40850   1504
12803   40743   1505
13295   40643   1525
13788   40534   1527
14280   40436   1550
14773   40331   1550
15265   40227   1574
15758   40135   1567
16250   40033   1558
16742   39942   1575
17235   39849   1590
17727   39757   1607
18220   39664   1625
18712   39560   1611
19205   39443   1570
19697   39303   1507
20189   39170   1463
20682   39052   1422
21174   38960   1400
21667   38882   1411
22159   38806   1400
22652   38740   1400
23144   38679   1394
23636   38619   1399
24129   38559   1392
24621   38510   1400
25114   38451   1400
25606   38408   1416
26098   38362   1425
26591   38313   1425
27083   38274   1436
27576   38226   1425
28068   38184   1425
28561   38150   1450
29053   38117   1454
29545   38084   1475
30038   38051   1486
30530   38019   1477
31023   37993   1500
31515   37962   1500
32008   37930   1501
32500   37907   1508
32992   37877   1508
33485   37851   1525
33977   37824   1515
34470   37795   1518
34962   37762   1523
35455   37719   1489
35947   37676   1480
36439   37635   1479
36932   37601   1500
37424   37568   1503
37917   37535   1525
38409   37488   1510
38902   37438   1524
39394   37373   1517
39886   37317   1525
40379   37260   1550
40871   37195   1550
41364   37116   1557
41856   37034   1575
42348   37004   1589
42841   36986   1600
43333   36962   1621
43826   36945   1674
44318   36916   1728
44811   36859   1808
45303   36668   1875
45795   36263   1983
46288   35673   2264
46780   34879   2876
47273   33699   4763
47765   33680   4800
48258   33680   4800
48750   33680   4800
>;
battery3_profile_t3_num = <100>;
battery3_profile_t3_col = <3>;
battery3_profile_t3 =
<
0       43480   2175
492     43203   2287
985     43045   2414
1477    42906   2473
1970    42762   2475
2462    42641   2506
2955    42509   2503
3447    42388   2525
3939    42258   2550
4432    42136   2550
4924    42008   2537
5417    41891   2556
5909    41769   2581
6402    41652   2585
6894    41536   2599
7386    41412   2592
7879    41296   2600
8371    41180   2600
8864    41071   2641
9356    40960   2650
9848    40854   2650
10341   40750   2686
10833   40645   2700
11326   40537   2722
11818   40428   2725
12311   40328   2750
12803   40221   2750
13295   40123   2764
13788   40024   2775
14280   39926   2775
14773   39825   2785
15265   39727   2775
15758   39628   2792
16250   39517   2767
16742   39392   2726
17235   39261   2675
17727   39131   2625
18220   39024   2625
18712   38931   2575
19205   38849   2595
19697   38776   2596
20189   38710   2612
20682   38644   2600
21174   38586   2620
21667   38526   2625
22159   38477   2652
22652   38420   2657
23144   38372   2669
23636   38329   2700
24129   38279   2700
24621   38240   2725
25114   38191   2725
25606   38158   2775
26098   38115   2782
26591   38082   2800
27083   38049   2825
27576   38008   2836
28068   37983   2875
28561   37950   2888
29053   37919   2904
29545   37894   2925
30038   37871   2950
30530   37849   2977
31023   37825   3000
31515   37806   3019
32008   37779   3026
32500   37753   3067
32992   37724   3100
33485   37691   3124
33977   37648   3140
34470   37605   3182
34962   37572   3223
35455   37524   3264
35947   37482   3350
36439   37425   3392
36932   37356   3450
37424   37296   3511
37917   37238   3614
38409   37163   3707
38902   37076   3804
39394   37001   3921
39886   36953   4069
40379   36919   4281
40871   36887   4626
41364   36851   5125
41856   36792   5901
42348   36682   7235
42841   36446   9655
43333   35998   15224
43826   35373   22919
44318   34428   21261
44811   33920   20250
45303   33920   20250
45795   33920   20250
46288   33920   20250
46780   33920   20250
47273   33920   20250
47765   33920   20250
48258   33920   20250
48750   33920   20250
>;
battery3_profile_t4_num = <100>;
battery3_profile_t4_col = <3>;
battery3_profile_t4 =
<
0       42980   4275
492     42628   4483
985     42358   4907
1477    42139   5212
1970    41976   5435
2462    41831   5562
2955    41699   5622
3447    41568   5675
3939    41448   5725
4432    41326   5745
4924    41203   5750
5417    41071   5778
5909    40957   5838
6402    40842   5910
6894    40726   5976
7386    40602   6017
7879    40473   6034
8371    40340   6075
8864    40218   6107
9356    40084   6125
9848    39946   6102
10341   39804   6100
10833   39673   6075
11326   39539   6075
11818   39423   6075
12311   39310   6075
12803   39219   6116
13295   39127   6136
13788   39046   6155
14280   38973   6182
14773   38894   6235
15265   38827   6301
15758   38752   6325
16250   38687   6383
16742   38621   6400
17235   38565   6475
17727   38509   6532
18220   38452   6573
18712   38397   6639
19205   38344   6705
19697   38294   6768
20189   38245   6812
20682   38196   6857
21174   38154   6920
21667   38106   6986
22159   38058   7027
22652   38018   7068
23144   37982   7144
23636   37940   7176
24129   37906   7225
24621   37877   7325
25114   37850   7424
25606   37808   7481
26098   37782   7613
26591   37742   7718
27083   37699   7854
27576   37656   7997
28068   37606   8161
28561   37565   8375
29053   37506   8543
29545   37449   8728
30038   37387   8939
30530   37326   9157
31023   37250   9343
31515   37185   9558
32008   37109   9779
32500   37043   10025
32992   36991   10271
33485   36951   10565
33977   36912   10882
34470   36872   11266
34962   36814   11677
35455   36712   12140
35947   36540   12666
36439   36227   13303
36932   35709   14181
37424   34976   15419
37917   33898   17453
38409   33740   17775
38902   33740   17775
39394   33740   17775
39886   33740   17775
40379   33740   17775
40871   33740   17775
41364   33740   17775
41856   33740   17775
42348   33740   17775
42841   33740   17775
43333   33740   17775
43826   33740   17775
44318   33740   17775
44811   33740   17775
45303   33740   17775
45795   33740   17775
46288   33740   17775
46780   33740   17775
47273   33740   17775
47765   33740   17775
48258   33740   17775
48750   33740   17775
>;
battery3_profile_t5_num = <100>;
battery3_profile_t5_col = <3>;
battery3_profile_t5 =
<
0       41310   9525
492     40895   9958
985     40582   10813
1477    40312   11447
1970    40082   11925
2462    39896   12255
2955    39732   12416
3447    39588   12527
3939    39467   12646
4432    39344   12605
4924    39219   12561
5417    39094   12730
5909    38994   12813
6402    38890   12875
6894    38808   12976
7386    38726   13034
7879    38654   13108
8371    38581   13198
8864    38521   13257
9356    38461   13314
9848    38412   13373
10341   38353   13425
10833   38304   13505
11326   38254   13568
11818   38215   13687
12311   38177   13779
12803   38144   13861
13295   38111   13959
13788   38078   14005
14280   38053   14087
14773   38022   14322
15265   37990   14502
15758   37957   14682
16250   37930   14933
16742   37891   15171
17235   37868   15442
17727   37825   15639
18220   37783   15907
18712   37744   16204
19205   37704   16483
19697   37646   16753
20189   37595   17037
20682   37544   17324
21174   37479   17592
21667   37413   17834
22159   37357   18133
22652   37281   18359
23144   37215   18582
23636   37159   18827
24129   37093   19041
24621   37041   19278
25114   36982   19447
25606   36926   19726
26098   36857   19952
26591   36757   20213
27083   36595   20454
27576   36351   20758
28068   35948   21086
28561   35324   21612
29053   34400   21016
29545   33980   19975
30038   33980   19975
30530   33980   19975
31023   33980   19975
31515   33980   19975
32008   33980   19975
32500   33980   19975
32992   33980   19975
33485   33980   19975
33977   33980   19975
34470   33980   19975
34962   33980   19975
35455   33980   19975
35947   33980   19975
36439   33980   19975
36932   33980   19975
37424   33980   19975
37917   33980   19975
38409   33980   19975
38902   33980   19975
39394   33980   19975
39886   33980   19975
40379   33980   19975
40871   33980   19975
41364   33980   19975
41856   33980   19975
42348   33980   19975
42841   33980   19975
43333   33980   19975
43826   33980   19975
44318   33980   19975
44811   33980   19975
45303   33980   19975
45795   33980   19975
46288   33980   19975
46780   33980   19975
47273   33980   19975
47765   33980   19975
48258   33980   19975
48750   33980   19975
>;

/* battery_prop_dim2_ext.dtsi */
/*vboot voltage for gauge 0%*/
g_PMIC_MIN_VOL_row = <4>;
g_PMIC_MIN_VOL_col = <10>;
g_PMIC_MIN_VOL =
<
	32700  32700  32700  32700
	32700  32700  32700  32700
	32700  32700  32700  32700
	32200  32200  32200  32200
	31000  31000  31000  31000
	31500  31500  31500  31500
	31000  31000  31000  31000
	31000  31000  31000  31000
	31000  31000  31000  31000
	31000  31000  31000  31200
>;
/*boot_up current for gauge 0%*/
g_PON_SYS_IBOOT_row = <4>;
g_PON_SYS_IBOOT_col = <10>;
g_PON_SYS_IBOOT =
<
	5000  5000  5000  5000
	5000  5000  5000  5000
	5000  5000  5000  5000
	5000  5000  5000  5000
	5000  5000  5000  5000
	5000  5000  5000  5000
	5000  5000  5000  5000
	5000  5000  5000  5000
	5000  5000  5000  5000
	5000  5000  5000  5000
>;
/*Pseudo1 hide percentage*/
g_QMAX_SYS_VOL_row = <4>;
g_QMAX_SYS_VOL_col = <10>;
g_QMAX_SYS_VOL =
<
	33600  33600  33600  33600
	33600  33600  33600  33600
	33600  33600  33600  33600
	33600  33600  33600  33600
	33600  33600  33600  33600
	32500  32500  32500  32500
	32800  32800  32800  32800
	32800  32800  32800  32800
	32800  32800  32800  32800
	32800  32800  32800  32800
>;
/*Pseudo100 percentage setting*/
g_FG_PSEUDO100_row = <4>;
g_FG_PSEUDO100_col = <10>;
g_FG_PSEUDO100 =
<
	100 100  95  95
	100 100  95  95
	100 100  95  95
	100 100  95  95
	100 100  95  95
	100 100  95  95
	100 100  95  95
	100 100  95  95
	100 100  95  95
	100 100  95  95
>;

	};
};

/* #include "../abc_spec_manager_type1.dtsi" */      /* From abc_spec_manager_type1.py */
&smd {
	sec_abc {
		compatible = "samsung,sec_abc";
		status = "okay";
		abc_spec_type1 {
			module_list = "gpu", "gpu_qc", "gpu_qc", "camera", "camera", "vib", "tsp", "tsp_sub";
			name_list = "gpu_fault", "gpu_fault", "gpu_page_fault", "mipi_overflow", "i2c_fail", "int_gnd_short", "tsp_int_fault", "tsp_int_fault";
#ifndef CONFIG_SEC_FACTORY
			threshold_cnt = <20>, <2>, <20>, <1>, <1>, <25>, <10>, <10>;
			threshold_time = <1200>, <1200>, <1200>, <0>, <0>, <5>, <5>, <5>;
#else
			threshold_cnt = <20>, <2>, <20>, <4>, <4>, <25>, <10>, <10>;
			threshold_time = <1200>, <1200>, <1200>, <120>, <120>, <5>, <5>, <5>;
#endif
		};
	};
};

/* #include "../ap_mtk_mt6877_T.dtsi" */             /* From ap_mtk_mt6877_T.py */
#include <dt-bindings/clock/mt6877-clk.h>
/* /home/dpi/qb5_8814/workspace/P4_1716/android/kernel/kmodule/ap/mtk/mt6877/ap_mtk_mt6877_T.a34x_eur.03.dtsi */
#include "../../mediatek/k6877ttv1_64_titan_black_tiger/board_00.dts"
#include "../../mediatek/k6877ttv1_64_titan_black_tiger/gpio_03.dtsi"

/* #include "../vt_muic.dtsi" */                     /* From vt_muic.py */
#if 0
&${jtag_usb_id_parent} {
	jtag_usb_id: jtag_usb_id {
		GPIO_CONFIG_PUD_DRV(${jtag_usb_id_gpio}, FUNC_INPUT_WAKEUP, PULL_NONE, DRV_LV1);
	};
};
#endif

&smd {
	vt_muic {
		compatible = "samsung,vt_muic";
		status = "okay";
#if 0
		pinctrl-names = "default";
		pinctrl-0 = <&jtag_usb_id>;
		vt_muic,usb_id = <SEC_GPIO_REF(${jtag_usb_id_gpio}) 0>;
#endif
#if 1
		use_battery_notifier_callback;
#endif
#if 1
		use_manager_notifier_callback;
#endif
	};
};


/* #include "../abc_common.dtsi" */                  /* From abc_common.py */
&smd {
	abc_hub {
		compatible = "samsung,abc_hub";
		status = "okay";
		bootc {
			bootc,time_spec_user = <100000>; /* user binary user build */
			bootc,time_spec_eng = <150000>; /* user binary eng build */
			bootc,time_spec_fac = <100000>; /* factory binary */
		};
	};
};

/* #include "../i2c-gpio.dtsi" */                    /* From i2c-gpio.py */
&pio {
       gpio_i2c_0_sda {
               gpio_i2c_0_sda_default: gpio_i2c_0_sda_default {
                       GPIO_CONFIG_PUD_DRV(AP,pio,163, FUNC_INPUT, PULL_NONE, DRV_LV1);
               };
       };
};

&pio {
       gpio_i2c_0_scl {
               gpio_i2c_0_scl_default: gpio_i2c_0_scl_default {
                       GPIO_CONFIG_PUD_DRV(AP,pio,162, FUNC_INPUT, PULL_NONE, DRV_LV1);
               };
       };
};

/ {
	fragment@model {
		target-path = "/";
	        __overlay__ {
			aliases {
				  i2c30 = "/i2c@30";
			};
			/* Software I2C */
			sw_i2c0: i2c@30 {
				cell-index = <30>;
				compatible = "i2c-gpio";
				gpios = <
					SEC_GPIO_REF(AP,pio,163) 0 /* SDA */
					SEC_GPIO_REF(AP,pio,162) 0 /* SCL */
					>;
				#i2c-gpio,delay-us = <2>;
				#address-cells = <1>;
				#size-cells = <0>;

				pinctrl-names = "default";
				pinctrl-0 = <
					&gpio_i2c_0_sda_default
					&gpio_i2c_0_scl_default
					>;

				status = "disabled";
			};
		};
	};
};


/* #include "../sm5451_charger.dtsi" */              /* From sm5451_charger.py */
&i2c10 {
	status = "okay";

	sm5451_charger: sm5451@63 {
		compatible = "siliconmitus,sm5451";
		reg = <0x63>;
	};
};

/* /home/dpi/qb5_8814/workspace/P4_1716/android/kernel/kmodule/battery/suwon/charger/sm5451/sm5451_charger.a34x.dtsi */
&sm5451_charger {
	sm5451,freq_byp = <0x1>; /* 375kHz */
	sm5451,freq = <2>; /* 500kHz */
	sm5451,r_ttl = <520000>;
	sm5451,topoff = <380>;
	sm5451,en_vbatreg = <1>;
};

/* #include "../isa1000_vibrator.dtsi" */            /* From isa1000_vibrator.py */
#define EXPAND(str) #str

&pio {
	/* add pinctrl for motor  */
	motor_pwm {
		motor_pwm_active: motor_pwm_active {
			pinmux = <PINMUX_GPIO0__FUNC_PWM_0>;
			bias-disable;
			output-low;
		  };
	};
};

&pio {
	vib_en_gpio: vib_en_gpio {
		pins_cmd_dat {
			pinmux = <MTK_PINMUX(SEC_GPIO_NUM(AP,pio,195), 0)>;
			slew-rate = <1>;
			bias-disable;
			output-low;
		};
	};
};


&smd {
	isa1000_vibrator {
		status = "okay";
		compatible = "imagis,isa1000_vibrator";
		isa1000,duty_ratio = <84>;
		isa1000,gpio_en = <SEC_GPIO_REF(AP,pio,195) 0>;
		isa1000,motor_type = EXPAND(LINEAR_1040);

#if 1
		/* for multi-frequency */
		isa1000,multi_frequency = <1>;
#endif
		/* frequency       alert low  mid  high  0  press release (multi_freq)*/
		isa1000,frequency = <2050>;

		pinctrl-names = "default";
		pinctrl-0 = <&motor_pwm_active &vib_en_gpio>;
	/*	#pwms = <&mtk_pwm 0 1000000>; */

		samsung,steps = <6>;
		samsung,intensities = <0 3000 4000 6000 8000 10000>;
		samsung,haptic_intensities = <0 2000 4000 6000 8000 10000>;
	};
};

/* #include "../sec_thermistor-1.dtsi" */            /* From sec_thermistor.py */
/ {
	fragment@smd {
		target-path = "/";
		__overlay__ {
			samsung_mobile_device {
				sec_pa_thermistor: sec_thermistor@1 {
					compatible = "samsung,sec-thermistor";
					status = "okay";
					thermistor_name = "sec-pa-thermistor";
					id = <1>;

					io-channels = SEC_ADC(auxadc,1);
					io-channel-names = "pa_therm";
					io-channel-ranges;
				};
			};
		};
	};
};

/* #include "../sec_thermistor-3.dtsi" */            /* From sec_thermistor.py */
/ {
	fragment@smd {
		target-path = "/";
		__overlay__ {
			samsung_mobile_device {
				sec_lp_thermistor: sec_thermistor@3 {
					compatible = "samsung,sec-thermistor";
					status = "okay";
					thermistor_name = "sec-lp-thermistor";
					id = <3>;

					io-channels = SEC_ADC(auxadc,4);
					io-channel-names = "lp_therm";
					io-channel-ranges;
				};
			};
		};
	};
};

/* #include "../sec_thermistor.dtsi" */              /* From sec_thermistor.py */
/ {
	fragment@smd {
		target-path = "/";
		__overlay__ {
			samsung_mobile_device {
				sec_ap_thermistor: sec_thermistor@0 {
					compatible = "samsung,sec-thermistor";
					status = "okay";
					thermistor_name = "sec-ap-thermistor";
					id = <0>;

					io-channels = SEC_ADC(auxadc,0);
					io-channel-names = "ap_therm";
					io-channel-ranges;
				};
			};
		};
	};
};

/* #include "../sec_thermistor-2.dtsi" */            /* From sec_thermistor.py */
/ {
	fragment@smd {
		target-path = "/";
		__overlay__ {
			samsung_mobile_device {
				sec_cp_thermistor: sec_thermistor@2 {
					compatible = "samsung,sec-thermistor";
					status = "okay";
					thermistor_name = "sec-cp-thermistor";
					id = <2>;

					io-channels = SEC_ADC(auxadc,2);
					io-channel-names = "cp_therm";
					io-channel-ranges;
				};
			};
		};
	};
};

/* /home/dpi/qb5_8814/workspace/P4_1716/android/kernel/kmodule/sec_pm/sec_thermistor/dts/sec_thermistor_mtk.a34x.03.dtsi */
&sec_ap_thermistor {
	adc_array = <84 102 124 149 174 210 240 287 356 411
				507 605 733 875 1061 1285 1519 1785 2086 2408
				2741 2982 3366>;

	temp_array = <900 850 800 750 700 650 600 550 500 450
				400 350 300 250 200 150 100 50 0 (-50)
				(-100) (-150) (-200)>;
};

&sec_pa_thermistor {
	adc_array = <332 397 468 555 634 752 879 977 1136 1316
				1544 1766 2019 2276 2567 2870 3141 3410 3660 3892
				4026 4095 4095>;

	temp_array = <900 850 800 750 700 650 600 550 500 450
				400 350 300 250 200 150 100 50 0 (-50)
				(-100) (-150) (-200)>;
};

&sec_cp_thermistor {
	adc_array = <335 399 469 557 636 754 846 977 1138 1317
				1548 1764 2009 2277 2436 2770 3029 3408 3665 3895
				4026 4095 4095>;

	temp_array = <900 850 800 750 700 650 600 550 500 450
				400 350 300 250 200 150 100 50 0 (-50)
				(-100) (-150) (-200)>;
};

&sec_lp_thermistor {
	adc_array = <324 390 463 548 592 701 802 914 1075 1225
				1450 1662 1908 2155 2451 2754 3026 3272 3533 3776
				3988 4095 4095>;

	temp_array = <900 850 800 750 700 650 600 550 500 450
				400 350 300 250 200 150 100 50 0 (-50)
				(-100) (-150) (-200)>;
};

/* #include "../hall_ic.dtsi" */                     /* From hall_ic.py */
/*
 * Hall ic device tree source
 *
 * Copyright (c) 2017 Samsung Electronics Co., Ltd.
 *		http://www.samsung.com
 *
 * This program is free software; you can redistribute it and/or modify
 * it under the terms of the GNU General Public License version 2 as
 * published by the Free Software Foundation.
 */

&smd {
	hall_ic: hall_ic {
		status = "okay";
		compatible = "hall_ic";
		pinctrl-names = "default";
		pinctrl-0 = <
#if 1
		&hall_irq
#endif
#if 0
		&certify_hall_irq
#endif
#if 0
		&hall_wacom_irq
#endif
		>;
#if 1
		hall_ic,debounce-interval = <50>;
#endif
#if 1
		hall: hall {
			name = "hall";
			event = <0x15>;
			gpios = <SEC_GPIO_REF(AP,pio,6) 1>;
		};
#endif
#if 0
		certify_hall: certify_hall {
			name = "certify_hall";
			event = <0x1b>;
			gpios = <SEC_GPIO_REF(${certify_hall_gpio}) 1>;
		};
#endif
#if 0
		hall_wacom: hall_wacom {
			name = "hall_wacom";
			event = <0x1e>;
			gpios = <SEC_GPIO_REF(${wacom_hall_gpio}) 1>;
		};
#endif
	};
};

#if 1
&pio {
	hall_irq: hall_irq {
		pinmux = <MTK_PINMUX(SEC_GPIO_NUM(AP,pio,6), 0)>;
		bias-disable;
	};
};
#endif

#if 0
&${certify_hall_parent} {
	certify_hall_irq: certify_hall_irq {
		pinmux = <MTK_PINMUX(SEC_GPIO_NUM(${certify_hall_gpio}), 0)>;
		bias-disable;
	};
};
#endif

#if 0
&${wacom_hall_parent} {
	hall_wacom_irq: hall_wacom_irq {
		pinmux = <MTK_PINMUX(SEC_GPIO_NUM(${wacom_hall_gpio}), 0)>;
		bias-disable;
	};
};
#endif
/* #include "../fingerprint_el7xx.dtsi" */           /* From fingerprint_el7xx.py */
/*
 * Copyright (c) 2012-2013, The Linux Foundation. All rights reserved.
 *
 * This program is free software; you can redistribute it and/or modify
 * it under the terms of the GNU General Public License version 2 and
 * only version 2 as published by the Free Software Foundation.
 *
 * This program is distributed in the hope that it will be useful,
 * but WITHOUT ANY WARRANTY; without even the implied warranty of
 * MERCHANTABILITY or FITNESS FOR A PARTICULAR PURPOSE.  See the
 * GNU General Public License for more details.
 */

&pio {
	btp_sleep: btp_sleep_enable {
		pins_cmd_dat{
			pinmux = <MTK_PINMUX(SEC_GPIO_NUM(AP,pio,121), 0)>;
			bias-pull-down;
			drive-strength = <1>;
		};
	};
	btp_ldo_en: btp_ldo_enable {
		pins_cmd_dat{
			pinmux = <MTK_PINMUX(SEC_GPIO_NUM(AP,pio,96), 0)>;
			bias-pull-down;
			drive-strength = <1>;
		};
	};
	spi5_set_miso: set_miso {
		pins_cmd_dat{
			pinmux = <MTK_PINMUX(SEC_GPIO_NUM(AP,pio,100), 1)>;
			drive-strength = <4>;
		};
	};
	spi5_set_cs: set_cs {
		pins_cmd_dat{
			pinmux = <MTK_PINMUX(SEC_GPIO_NUM(AP,pio,99), 1)>;
			drive-strength = <4>;
		};
	};
	spi5_set_mosi: set_mosi {
		pins_cmd_dat{
			pinmux = <MTK_PINMUX(SEC_GPIO_NUM(AP,pio,101), 1)>;
			drive-strength = <4>;
		};
	};
	spi5_set_clk: set_clk {
		pins_cmd_dat{
			pinmux = <MTK_PINMUX(SEC_GPIO_NUM(AP,pio,98), 1)>;
			drive-strength = <4>;
		};
	};
	spi5_clr_miso: clr_miso {
		pins_cmd_dat{
			pinmux = <MTK_PINMUX(SEC_GPIO_NUM(AP,pio,100), 0)>;
			slew-rate = <0>;
			bias-pull-down;
			input-enable;
			drive-strength = <1>;
		};
	};
	spi5_clr_cs: clr_cs {
		pins_cmd_dat{
			pinmux = <MTK_PINMUX(SEC_GPIO_NUM(AP,pio,99), 0)>;
			slew-rate = <0>;
			bias-pull-down;
			output-low;
			drive-strength = <1>;
		};
	};
	spi5_clr_mosi: clr_mosi {
		pins_cmd_dat{
			pinmux = <MTK_PINMUX(SEC_GPIO_NUM(AP,pio,101), 0)>;
			slew-rate = <0>;
			bias-pull-down;
			output-low;
			drive-strength = <1>;
		};
	};
	spi5_clr_clk: clr_clk {
		pins_cmd_dat{
			pinmux = <MTK_PINMUX(SEC_GPIO_NUM(AP,pio,98), 0)>;
			slew-rate = <0>;
			bias-pull-down;
			output-low;
			drive-strength = <1>;
		};
	};
};

#if defined(CONFIG_SEC_FACTORY) || !1
&spi5 {
	status = "okay";
	max-dma = <0x40000>;
#else
&smd {
#endif
	#address-cells = <1>;
	#size-cells = <0>;

	etspi-spi@0 {
		compatible = "etspi,el7xx";
		reg = <0x00>;
		spi-max-frequency = <25000000>;
#if !defined(CONFIG_SEC_FACTORY) && 1
		clocks = <&topckgen_clk CLK_TOP_MAINPLL_D5_D4>,
			<&topckgen_clk CLK_TOP_SPI_SEL>,
			<&infracfg_ao_clk CLK_IFRAO_SPI5>;
		clock-names = "parent-clk", "sel-clk", "spi-clk";
#endif

		pinctrl-names = "default", "pins_poweron", "pins_poweroff";
		pinctrl-0 = <&btp_sleep &btp_ldo_en>;
		pinctrl-1 = <&spi5_set_miso &spi5_set_cs &spi5_set_mosi &spi5_set_clk>;
		pinctrl-2 = <&spi5_clr_miso &spi5_clr_cs &spi5_clr_mosi &spi5_clr_clk>;


		gpio-controller;
		#gpio-cells = <2>;

		etspi-sleepPin = <SEC_GPIO_REF(AP,pio,121) 0>;
		etspi-ldoPin = <SEC_GPIO_REF(AP,pio,96) 0>;
		etspi-chipid = "EL721";
		etspi-modelinfo = "A346";
		etspi-position = "11.69,0.00,9.10,9.10,14.80,14.80,12.00,12.00,5.00";
		etspi-rb = "588,-1,-1,FFFFFF";
		controller-data {
			mediatek,tckdly = <1>;
		};
	};
};

/* #include "../pmic_MT6360.dtsi" */                 /* From pmic_MT6360.py */
#if 1800000 && 1800000
&mt_pmic_vfp_ldo_reg {
    regulator-min-microvolt = <1800000>;
    regulator-max-microvolt = <1800000>;
    
     
};
#endif

#if 1800000 && 1800000
&mt_pmic_vtp_ldo_reg {
    regulator-min-microvolt = <1800000>;
    regulator-max-microvolt = <1800000>;
    regulator-always-on;regulator-boot-on;
     
};
#endif

#if 0 && 0
&mt_pmic_vmc_ldo_reg {
    regulator-min-microvolt = <0>;
    regulator-max-microvolt = <0>;
    
     
};
#endif

#if 0 && 0
&mt_pmic_vmch_ldo_reg {
    regulator-min-microvolt = <0>;
    regulator-max-microvolt = <0>;
    
     
};
#endif

#if 0 && 0
&mt_pmic_vdram2_ldo_reg {
    regulator-min-microvolt = <0>;
    regulator-max-microvolt = <0>;
    
     
};
#endif
/* #include "../pmic_MT6365.dtsi" */                 /* From pmic_MT6365.py */
#if 0 && 0
&mt_pmic_vaud18_ldo_reg {
    regulator-min-microvolt = <0>;
    regulator-max-microvolt = <0>;
    
     
};
#endif

#if 0 && 0
&mt_pmic_vsim1_ldo_reg {
    regulator-min-microvolt = <0>;
    regulator-max-microvolt = <0>;
    
     
};
#endif

#if 3300000 && 3300000
&mt_pmic_vibr_ldo_reg {
    regulator-min-microvolt = <3300000>;
    regulator-max-microvolt = <3300000>;
    regulator-always-on;regulator-boot-on;
     
};
#endif

#if 0 && 0
&mt_pmic_vrf12_ldo_reg {
    regulator-min-microvolt = <0>;
    regulator-max-microvolt = <0>;
    
     
};
#endif

#if 0 && 0
&mt_pmic_vusb_ldo_reg {
    regulator-min-microvolt = <0>;
    regulator-max-microvolt = <0>;
    
     
};
#endif

#if 0 && 0
&mt_pmic_vsram_proc2_ldo_reg {
    regulator-min-microvolt = <0>;
    regulator-max-microvolt = <0>;
    
     
};
#endif

#if 0 && 0
&mt_pmic_vio18_ldo_reg {
    regulator-min-microvolt = <0>;
    regulator-max-microvolt = <0>;
    
     
};
#endif

#if 0 && 0
&mt_pmic_vcamio_ldo_reg {
    regulator-min-microvolt = <0>;
    regulator-max-microvolt = <0>;
    
     
};
#endif

#if 0 && 0
&mt_pmic_vcn18_ldo_reg {
    regulator-min-microvolt = <0>;
    regulator-max-microvolt = <0>;
    
     
};
#endif

#if 0 && 0
&mt_pmic_vfe28_ldo_reg {
    regulator-min-microvolt = <0>;
    regulator-max-microvolt = <0>;
    
     
};
#endif

#if 0 && 0
&mt_pmic_vcn13_ldo_reg {
    regulator-min-microvolt = <0>;
    regulator-max-microvolt = <0>;
    
     
};
#endif

#if 0 && 0
&mt_pmic_vcn33_1_bt_ldo_reg {
    regulator-min-microvolt = <0>;
    regulator-max-microvolt = <0>;
    
     
};
#endif

#if 0 && 0
&mt_pmic_vcn33_1_wifi_ldo_reg {
    regulator-min-microvolt = <0>;
    regulator-max-microvolt = <0>;
    
     
};
#endif

#if 0 && 0
&mt_pmic_vaux18_ldo_reg {
    regulator-min-microvolt = <0>;
    regulator-max-microvolt = <0>;
    
     
};
#endif

#if 0 && 0
&mt_pmic_vsram_others_ldo_reg {
    regulator-min-microvolt = <0>;
    regulator-max-microvolt = <0>;
    
     
};
#endif

#if 0 && 0
&mt_pmic_vefuse_ldo_reg {
    regulator-min-microvolt = <0>;
    regulator-max-microvolt = <0>;
    
     
};
#endif

#if 0 && 0
&mt_pmic_vxo22_ldo_reg {
    regulator-min-microvolt = <0>;
    regulator-max-microvolt = <0>;
    
     
};
#endif

#if 0 && 0
&mt_pmic_vrfck_ldo_reg {
    regulator-min-microvolt = <0>;
    regulator-max-microvolt = <0>;
    
     
};
#endif

#if 0 && 0
&mt_pmic_vbif28_ldo_reg {
    regulator-min-microvolt = <0>;
    regulator-max-microvolt = <0>;
    
     
};
#endif

#if 3000000 && 3000000
&mt_pmic_vio28_ldo_reg {
    regulator-min-microvolt = <3000000>;
    regulator-max-microvolt = <3000000>;
    
     
};
#endif

#if 0 && 0
&mt_pmic_vemc_ldo_reg {
    regulator-min-microvolt = <0>;
    regulator-max-microvolt = <0>;
    
     
};
#endif

#if 0 && 0
&mt_pmic_vcn33_2_bt_ldo_reg {
    regulator-min-microvolt = <0>;
    regulator-max-microvolt = <0>;
    
     
};
#endif

#if 0 && 0
&mt_pmic_vcn33_2_wifi_ldo_reg {
    regulator-min-microvolt = <0>;
    regulator-max-microvolt = <0>;
    
     
};
#endif

#if 0 && 0
&mt_pmic_va12_ldo_reg {
    regulator-min-microvolt = <0>;
    regulator-max-microvolt = <0>;
    
     
};
#endif

#if 0 && 0
&mt_pmic_va09_ldo_reg {
    regulator-min-microvolt = <0>;
    regulator-max-microvolt = <0>;
    
     
};
#endif

#if 0 && 0
&mt_pmic_vrf18_ldo_reg {
    regulator-min-microvolt = <0>;
    regulator-max-microvolt = <0>;
    
     
};
#endif

#if 0 && 0
&mt_pmic_vsram_md_ldo_reg {
    regulator-min-microvolt = <0>;
    regulator-max-microvolt = <0>;
    
     
};
#endif

#if 0 && 0
&mt_pmic_vufs_ldo_reg {
    regulator-min-microvolt = <0>;
    regulator-max-microvolt = <0>;
    
     
};
#endif

#if 0 && 0
&mt_pmic_vm18_ldo_reg {
    regulator-min-microvolt = <0>;
    regulator-max-microvolt = <0>;
    
     
};
#endif

#if 0 && 0
&mt_pmic_vbbck_ldo_reg {
    regulator-min-microvolt = <0>;
    regulator-max-microvolt = <0>;
    
     
};
#endif

#if 0 && 0
&mt_pmic_vsram_proc1_ldo_reg {
    regulator-min-microvolt = <0>;
    regulator-max-microvolt = <0>;
    
     
};
#endif

#if 0 && 0
&mt_pmic_vsim2_ldo_reg {
    regulator-min-microvolt = <0>;
    regulator-max-microvolt = <0>;
    
     
};
#endif

/* #include "../s2mpb03.dtsi" */                     /* From s2mpb03.py */
&sw_i2c0 {
	#address-cells = <1>;
	#size-cells = <0>;
	status = "okay";
	s2mpb03_pmic@56 {
		compatible = "samsung,s2mpb03pmic";
		reg = <0x56>;
		s2mpb03,wakeup;

		regulators {
			s2mpb03_0_l1: s2mpb03-ldo1 {
				regulator-name = "CAM0_s2mpb03-l1";
				regulator-min-microvolt = <1050000>;
				regulator-max-microvolt = <1050000>;
				
				 
			};

			s2mpb03_0_l2: s2mpb03-ldo2 {
				regulator-name = "CAM0_s2mpb03-l2";
				regulator-min-microvolt = <1100000>;
				regulator-max-microvolt = <1100000>;
				
				 
			};

			s2mpb03_0_l3: s2mpb03-ldo3 {
				regulator-name = "CAM0_s2mpb03-l3";
				regulator-min-microvolt = <1800000>;
				regulator-max-microvolt = <1800000>;
				
				 
			};

			s2mpb03_0_l4: s2mpb03-ldo4 {
				regulator-name = "CAM0_s2mpb03-l4";
				regulator-min-microvolt = <1100000>;
				regulator-max-microvolt = <1100000>;
				
				 
			};

			s2mpb03_0_l5: s2mpb03-ldo5 {
				regulator-name = "CAM0_s2mpb03-l5";
				regulator-min-microvolt = <2150000>;
				regulator-max-microvolt = <2150000>;
				
				 
			};

			s2mpb03_0_l6: s2mpb03-ldo6 {
				regulator-name = "CAM0_s2mpb03-l6";
				regulator-min-microvolt = <2800000>;
				regulator-max-microvolt = <2800000>;
				
				 
			};

			s2mpb03_0_l7: s2mpb03-ldo7 {
				regulator-name = "CAM0_s2mpb03-l7";
				regulator-min-microvolt = <2800000>;
				regulator-max-microvolt = <2800000>;
				
				 
			};
		};
	};
};

/* #include "../sec_direct_charger.dtsi" */          /* From sec_direct_charger.py */

&smd {
	sec-direct-charger {
		status = "okay";
		compatible = "samsung,sec-direct-charger";

		charger,battery_name = "battery";
		charger,main_charger = "mtk-charger";
		charger,direct_charger = "sm5451-charger";

		charger,dchg_min_current = <2000>;

		charger,ta_alert_wa;
	};
};


/* /home/dpi/qb5_8814/workspace/P4_1716/android/kernel/kmodule/battery/suwon/common/sec_direct_charger/dts/a34x/sec_direct_charger.dtsi */

&smd {
	pass-through {
		start_delay = <5000>; /* msec */
		init_delay = <5000>; /* msec */
		min_cap = <200>; /* 0.1 % */
		fixed_sc_cap = <900>; /* 0.1 % */
		max_icl = <3000>; /* mA */
		vfloat = <4440>; /* mV */
	};
};


/* #include "../sensorhub_shub.dtsi" */              /* From sensorhub_shub.py */
#if 1
&mt_pmic_vtp_ldo_reg {
	regulator-name = "VDD_SENSOR_1P8";
};
#endif
#if 0
&${gpio_sensor_ldo_en_parent} {
	shub_sensor_ldo_en: shub-sensor-ldo-en {
		samsung,pins = SEC_GPIO(${gpio_sensor_ldo_en});
		samsung,pin-function = <1>;
		samsung,pin-pud = <0>;
		samsung,pin-con-pdn = <3>;
		samsung,pin-pud-pdn = <0>;
	};
};
#endif
/ {
	fragment@model {
		target-path = "/";
		__overlay__ {
			shub {
#if 0
    			pinctrl-names = "default";
				pinctrl-0 = <&shub_sensor_ldo_en>;
#endif
#if 1
				sensor-vdd-regulator = "VDD_SENSOR_1P8";
#endif

#if 0
				mag-check-nfc = <SEC_GPIO_REF(${gpio_nfc_check}) 0>;
#endif

#if 0
				pogo-int = <SEC_GPIO_REF(${gpio_pogo_int}) 0>;
#endif

#if 0
				sensor-ldo-en = <SEC_GPIO_REF(${gpio_sensor_ldo_en}) 0>;
#endif
			};
		};
	};
};

/* #include "../nfc_lsi.dtsi" */                     /* From nfc_lsi.py */
/*
 * This program is free software; you can redistribute it and/or modify
 * it under the terms of the GNU General Public License version 2 and
 * only version 2 as published by the Free Software Foundation.
 *
 * This program is distributed in the hope that it will be useful,
 * but WITHOUT ANY WARRANTY; without even the implied warranty of
 * MERCHANTABILITY or FITNESS FOR A PARTICULAR PURPOSE.  See the
 * GNU General Public License for more details.
 */

#if 0
#if 0
&${ese_check_parent} {
	ese_check_default: check_default {
		pins_cmd_dat {
			pinmux = <MTK_PINMUX(SEC_GPIO_NUM(${ese_check}), 0)>;
			input-enable;
			bias-disable;
		};
	};
};
#endif

&${ese_spi_parent} {
	ese_spi_bus: ese_spi_bus {
		pins_cmd_dat {
			/* spi func is 2, but this can be different by AP */
			pinmux = <MTK_PINMUX(SEC_GPIO_NUM(${ese_spi_miso}), 2)>,
				<MTK_PINMUX(SEC_GPIO_NUM(${ese_spi_mosi}), 2)>,
				<MTK_PINMUX(SEC_GPIO_NUM(${ese_spi_cs}), 2)>,
				<MTK_PINMUX(SEC_GPIO_NUM(${ese_spi_clk}), 2)>;
			bias-disable;
		};
	};

	ese_spi_bus_suspend: ese_spi_bus_suspend {
		pins_cmd_dat {
			/* spi func is 2, but this can be different by AP */
			pinmux = <MTK_PINMUX(SEC_GPIO_NUM(${ese_spi_miso}), 0)>,
				<MTK_PINMUX(SEC_GPIO_NUM(${ese_spi_mosi}), 0)>,
				<MTK_PINMUX(SEC_GPIO_NUM(${ese_spi_clk}), 0)>;
			input-enable;
			bias-pull-down;
		};
	};

	/*need cs pin controlled by ese driver*/
	ese_spi_cs: ese_spi_cs {
		pins_cmd_dat {
			pinmux = <MTK_PINMUX(SEC_GPIO_NUM(${ese_spi_cs}), 0)>;
			output-high;
			bias-disable;
		};
	};

	ese_spi_cs_suspend: ese_spi_cs_suspend {
		pins_cmd_dat {
			pinmux = <MTK_PINMUX(SEC_GPIO_NUM(${ese_spi_cs}), 0)>;
			output-high;
			bias-disable;
		};
	};
};

&${ese_spi} {
	status = "ok";
	pinctrl-names = "ese_active", "ese_suspend";
	pinctrl-0 = <&ese_spi_bus>;
	pinctrl-1 = <&ese_spi_bus_suspend &ese_spi_cs_suspend>;

	ese_spi@0 {
		compatible = "ese_p3";
		reg = <0>;
		spi-max-frequency = <7000000>;
#if 0
		ese-det-gpio = <SEC_GPIO_REF(${ese_check}) 0>;
		pinctrl-names = "default";
		pinctrl-0 = <&ese_check_default>;
#endif
#if 0
		p3-vdd-supply = <&${ese_pvdd_ldo}>;
#endif
		/*need cs pin controlled by ese driver*/
		/*ese_p3,cs-gpio = <SEC_GPIO_REF(${ese_spi_cs}) 0>;*/
	};
};

#if 0
/ {
	fragment@ese_platform {
		target-path = "/";
		__overlay__ {
			ese_platform {
				compatible = "p3_platform";
			};
		};
	};
};
#endif
#endif


&pio {
	nfc_ven: nfc_ven {
		pins_cmd_dat{
			pinmux = <MTK_PINMUX(SEC_GPIO_NUM(AP,pio,107), 0)>;
			output-high;
			bias-disable;
		};
	};
	ven_nc: ven_nc {
		pins_cmd_dat{
			pinmux = <MTK_PINMUX(SEC_GPIO_NUM(AP,pio,107), 0)>;
			input-enable;
			bias-pull-down;
		};
	};
};

&pio {
	nfc_firm: nfc_firm {
		pins_cmd_dat{
			pinmux = <MTK_PINMUX(SEC_GPIO_NUM(AP,pio,108), 0)>;
			output-low;
			bias-disable;
		};
	};
	firm_nc: firm_nc {
		pins_cmd_dat{
			pinmux = <MTK_PINMUX(SEC_GPIO_NUM(AP,pio,108), 0)>;
			input-enable;
			bias-pull-down;
		};
	};
};

&pio {
	nfc_clk_req: nfc_clk_req {
		pins_cmd_dat{
			pinmux =  <MTK_PINMUX(SEC_GPIO_NUM(AP,pio,13), 0)>;
			input-enable;
			bias-pull-down;
		};
	};
	clk_req_nc: clk_req_nc {
		pins_cmd_dat{
			pinmux =  <MTK_PINMUX(SEC_GPIO_NUM(AP,pio,13), 0)>;
			input-enable;
			bias-pull-down;
		};
	};
};

&pio {
	nfc_irq: nfc_irq {
		pins_cmd_dat {
			pinmux = <MTK_PINMUX(SEC_GPIO_NUM(AP,pio,11), 0)>;
			input-enable;
			bias-pull-down;
		};
	};

	irq_nc: irq_nc {
		pins_cmd_dat {
			pinmux = <MTK_PINMUX(SEC_GPIO_NUM(AP,pio,11), 0)>;
			input-enable;
			bias-pull-down;
		};
	};
};

#if 1
&pio {
	nfc_check: nfc_check {
		pins_cmd_dat {
			pinmux = <MTK_PINMUX(SEC_GPIO_NUM(AP,pio,90), 0)>;
			input-enable;
			bias-disable;
		};
	};
};
#endif

#if 0
&${sw_parent} {
	nfc_sw: nfc_sw {
		pins_cmd_dat {
			pinmux = <MTK_PINMUX(SEC_GPIO_NUM(${sw_gpio}), 0)>;
			output-low;
			bias-disable;
		};
	};
	sw_nc: sw_nc {
		pins_cmd_dat {
			pinmux = <MTK_PINMUX(SEC_GPIO_NUM(${sw_gpio}), 0)>;
			input-enable;
			bias-pull-down;
		};
	};
};
#endif

&i2c3 {
	status = "ok";
	clock-frequency = <400000>;
	mediatek,use-open-drain;
	sec_nfc: sec-nfc@27 {
		compatible = "sec-nfc";
		reg = <0x27>;
		interrupt-parent = <&pio>;
		interrupts = <SEC_GPIO_NUM(AP,pio,11) IRQ_TYPE_EDGE_RISING
			SEC_GPIO_NUM(AP,pio,11) 0>;
		sec-nfc,irq-gpio = <SEC_GPIO_REF(AP,pio,11) 0>;
		sec-nfc,ven-gpio = <SEC_GPIO_REF(AP,pio,107) 0>;
		sec-nfc,firm-gpio = <SEC_GPIO_REF(AP,pio,108) 0>;
		sec-nfc,clk_req-gpio = <SEC_GPIO_REF(AP,pio,13) 0>;
#if 1
		nfc_pvdd-supply = <&mt_pmic_vfp_ldo_reg>;
#endif
#if 1
		sec-nfc,check_nfc = <SEC_GPIO_REF(AP,pio,90) 0>;
#endif
#if 0
		sec-nfc,coldreset-gpio = <SEC_GPIO_REF(${ese_reset}) 0>;
#endif
		sec-nfc,clk_req_wake;
		sec-nfc,ldo_control;
/*		sec-nfc,pvdd-gpio = <&pio 154 0>;*/
#if 0
		sec-nfc,sw-gpio = <SEC_GPIO_REF(${sw_gpio}) 0>;
#endif
		sec-nfc,bootloader_ver = <6>;
		/*sec-nfc,irq_all_trigger;*/
		pinctrl-names = "default", "nfc_nc";

		pinctrl-0 = <&nfc_ven &nfc_firm &nfc_clk_req &nfc_irq
#if 1
					&nfc_check 
#endif
#if 0
					&nfc_sw
#endif
					>;
		pinctrl-1 = <&ven_nc &firm_nc &clk_req_nc &irq_nc
#if 0
					&sw_nc
#endif
					>;
	};
};

/* #include "../input_berlin.dtsi" */                /* From input_berlin.py */
&pio {
	berlin_attn_irq: berlin_attn_irq {
		GPIO_CONFIG_PUD(AP,pio,14, FUNC_INPUT_WAKEUP, PULL_NONE);
	};

	berlin_attn_irq_suspend: berlin_attn_irq_suspend {
		GPIO_CONFIG_PUD(AP,pio,14, FUNC_INPUT, PULL_NONE);
	};
};

&i2c0 {
	#address-cells = <1>;
	#size-cells = <0>;
	status = "okay";
	clock-frequency = <400000>;

	tsp_goodix: touchscreen@5d {
		status = "okay";
		compatible = "goodix,berlin";
		reg = <0x5d>;
		pinctrl-names = "on_state", "off_state";
		pinctrl-0 = <&berlin_attn_irq>;
		pinctrl-1 = <&berlin_attn_irq_suspend>;
		tsp_io_ldo-supply = <&NC>;
		tsp_avdd_ldo-supply = <&mt_pmic_vio28_ldo_reg>;
		sec,irq_gpio = <SEC_GPIO_REF(AP,pio,14) 0>;
		sec,irq_flag = <0x2002>; /* IRQF_TRIGGER_FALLING | IRQF_ONESHOT */
		support_dex_mode;
		sec,enable_sysinput_enabled;
		support_open_short_test;
	};
};

/* /home/dpi/qb5_8814/workspace/P4_1716/android/kernel/kmodule/input/touchscreen/goodix/berlin/dts/input-mtk-tsp-berlin.a34x.dtsi */
&tsp_goodix {
	status = "okay";
	/delete-property/ tsp_io_ldo-supply;
	not_support_io_ldo;
	support_ear_detect_mode;
	support_fod;
	support_fod_lp_mode;
	enable_settings_aot;
	sec,bitmask_unload = <12 0x804>; /* bitshift bitmask. this is for focaltech panel */
	sec,refresh_rate_enable;
	sec,enable_esd_check;

	sec,max_coords = <1080 2400>;
	//sec,firmware_name = "gt9895_a33x.bin";
	sec,bringup = <1>;

	sec,ic_type = <2>; //GT9895
	sec,max_drv_num = <17>;
	sec,max_sen_num = <35>;
	sec,drv_map = <35 36 37 38 39 40 41 42 43 44
			45 46 47 48 49 50 51>;
	sec,sen_map = <0 1 2 3 4 5 6 7 8 9 10 11 12
			13 14 15 16 17 18 19 20 21
			22 23 24 25 26 27 28 29 30
			31 32 33 34>;
	sec,short_test_time_reg = <0x1479E>;
	sec,short_test_status_reg = <0x13400>;
	sec,short_test_result_reg = <0x13408>;
	sec,drv_drv_reg = <0x13446>;
	sec,sen_sen_reg = <0x136EE>;
	sec,drv_sen_reg = <0x14152>;
	sec,diff_code_reg = <0x14734>;
	sec,production_test_addr = <0x15D4C>;
	sec,switch_freq_cmd = <0xB1>;
	sec,switch_cfg_cmd = <0x64>;
	sec,snr_cmd = <0x65>;
	sec,sensitive_cmd = <0x66>;

	sec,isp_ram_reg = <0x23800>;
	sec,flash_cmd_reg = <0x12400>;
	sec,isp_buffer_reg = <0x12410>;
	sec,config_data_reg = <0x3E000>;
	sec,misctl_reg = <0xD804>;
	sec,watch_dog_reg = <0xD040>;
	sec,config_id_reg = <0x10076>;
	sec,enable_misctl_val = <0x20700000>;
};

/* /home/dpi/qb5_8814/workspace/P4_1716/android/kernel/kmodule/input/touchscreen/goodix/berlin/dts/input-mtk-tsp-berlin.a34x.01.dtsi */
&tsp_goodix {
	sec,max_coords = <1080 2340>;
	sec,firmware_name = "tsp_goodix/gt9895_a34x.bin";
	sec,bringup = <0>;
};

/* #include "../sensors_isg5320a.dtsi" */            /* From sensors_isg5320a.py */
#if 1

&i2c7 {
	#address-cells = <1>;
	#size-cells = <0>;
	status = "okay";
	clock-frequency = <400000>;
	pinctrl-names = "default";
#if 0
	pinctrl-0 = <&grip_ldo_en>;
#endif

	isg5320a: isg5320a-i2c@2C {
		compatible = "isg5320a";
		status = "okay";
		reg = <0x2C>;
		pinctrl-names = "default";
		pinctrl-0 = <&grip_int>;

		interrupt-parent = <SEC_GPIO_TYPE(AP,pio,17)>;
		interrupts = <SEC_GPIO_NUM(AP,pio,17) 0>;

		isg5320a,irq-gpio = <SEC_GPIO_REF(AP,pio,17) 0>;
		isg5320a,hallic_detect = <1>;
		isg5320a,hallic_cert_detect = <1>;

		isg5320a,reg_num = <150>;
	};
};

&pio {
	grip_int: grip-int {
		pins_cmd_dat {
			pinmux = <MTK_PINMUX(SEC_GPIO_NUM(AP,pio,17), 0)>;
			slew-rate = <0>;
			bias-disable;
		};
	};
};

#if 0
&${gpio_grip_en_parent} {
	grip_ldo_en: grip-ldo-en {
		pins_cmd_dat {
			pinmux = <MTK_PINMUX(SEC_GPIO_NUM(${gpio_grip_en}), 0)>;
			slew-rate = <1>;
			bias-disable;
			output-high;
		};
	};
};
#endif

#if 0
&pio {
	grip_i2c: grip-i2c {
		pins_cmd0_dat {
			pinmux = <MTK_PINMUX(SEC_GPIO_NUM(AP,pio,135), 0)>;
			slew-rate = <0>;
			bias-disable;
		};
		pins_cmd1_dat {
			pinmux = <MTK_PINMUX(SEC_GPIO_NUM(AP,pio,134), 0)>;
			slew-rate = <0>;
			bias-disable;
		};
	};
};
#endif
#endif /*isg5320a*/



#if 0

&${i2c_grip_sub} {
	#address-cells = <1>;
	#size-cells = <0>;
	status = "okay";
	clock-frequency = <400000>;
	pinctrl-names = "default";
#if 0
	pinctrl-0 = <&grip_sub_ldo_en>;
#endif
	isg5320a_sub: isg5320a-sub-i2c@28 {
		compatible = "isg5320a_sub";
		status = "okay";
		reg = <0x28>;
		pinctrl-names = "default";
		pinctrl-0 = <&grip_sub_int>;

		interrupt-parent = <SEC_GPIO_TYPE(${gpio_grip_sub_irq})>;
		interrupts = <SEC_GPIO_NUM(${gpio_grip_sub_irq}) 0>;

		isg5320a_sub,irq-gpio = <SEC_GPIO_REF(${gpio_grip_sub_irq}) 0>;
		isg5320a_sub,hallic_detect = <1>;
		isg5320a_sub,hallic_cert_detect = <1>;

		isg5320a_sub,reg_num = <150>;
	};
};

&${gpio_grip_sub_irq_parent} {
	grip_sub_int: grip-sub-int {
		pins_cmd_dat {
			pinmux = <MTK_PINMUX(SEC_GPIO_NUM(${gpio_grip_sub_irq}), 0)>;
			slew-rate = <0>;
			bias-disable;
		};
	};
};

#if 0
&${gpio_grip_en_parent} {
	grip_sub_ldo_en: grip-sub-ldo-en {
		pins_cmd_dat {
			pinmux = <MTK_PINMUX(SEC_GPIO_NUM(${gpio_grip_sub_en}), 0)>;
			slew-rate = <1>;
			bias-disable;
			output-high;
		};
	};
};
#endif

#if 0
&${gpio_grip_sub_i2c_parent} {
	grip_sub_i2c: grip-sub-i2c {
		pins_cmd0_dat {
			pinmux = <MTK_PINMUX(SEC_GPIO_NUM(${gpio_grip_sub_i2c_sda}), 0)>;
			slew-rate = <0>;
			bias-disable;
		};
		pins_cmd1_dat {
			pinmux = <MTK_PINMUX(SEC_GPIO_NUM(${gpio_grip_sub_i2c_scl}), 0)>;
			slew-rate = <0>;
			bias-disable;
		};
	};
};
#endif

#endif /*isg5320a_sub*/

/* /home/dpi/qb5_8814/workspace/P4_1716/android/kernel/kmodule/sensors/isg5320a/dts/isg5320a_mtk.a34x.dtsi */
&isg5320a {
	reg = <0x28>;
	isg5320a,hallic_detect = <0>;
	isg5320a,hallic_cert_detect = <0>;
	isg6320,reg_num = <151>;
	isg5320a,set_reg = /bits/ 8 <
		0x05 0xFC
		0x06 0xF0
		0x07 0x13
		0x08 0x01
		0x09 0x80
		0x0A 0x20
		0x0B 0x00
		0x0C 0x00
		0x12 0x89
		0x19 0x8A
		0x1B 0x22
		0x1D 0x19
		0x1E 0x00
		0x1F 0x18
		0x20 0x05
		0x21 0x10
		0x22 0x10
		0x23 0x00
		0x24 0x00
		0x25 0x05
		0x26 0x05
		0x27 0x10
		0x28 0x19
		0x29 0x00
		0x2A 0x19
		0x2B 0x00
		0x2C 0x00
		0x2D 0x19
		0x2F 0x18
		0x30 0xC0
		0x41 0x11
		0x60 0xF0
		0x61 0x8F
		0x62 0x07
		0x63 0x00
		0x64 0x00
		0x65 0x44
		0x66 0x3C
		0x67 0x01
		0x68 0x00
		0x69 0x00
		0x6A 0x10
		0x6B 0x00
		0x6C 0x10
		0x6D 0x40
		0x6E 0x22
		0x6F 0x00
		0x70 0x01
		0x71 0x60
		0x72 0xFF
		0x73 0xFF
		0x74 0xFF
		0x7B 0x08
		0x7C 0x00
		0x7D 0x0C
		0x7E 0x00
		0x7F 0xF8
		0x80 0xF8
		0x81 0x00
		0x82 0xF0
		0x83 0xF0
		0x84 0xF0
		0x85 0xF0
		0x86 0xF0
		0x87 0xF0
		0x88 0x00
		0x89 0x00
		0x8A 0x08
		0x8B 0x00
		0x8C 0x02
		0x8D 0x00
		0x99 0x21
		0x9A 0x3C
		0x9B 0x01
		0x9C 0x2C
		0x9D 0x00
		0x9E 0x00
		0x9F 0x00
		0xA0 0x96
		0xA1 0xC0
		0xA2 0x22
		0xA3 0x00
		0xA4 0x08
		0xA5 0x60
		0xA6 0xFF
		0xA7 0xFF
		0xA8 0xFF
		0xA9 0x00
		0xAF 0x40
		0xB0 0x00
		0xB1 0x60
		0xB2 0x00
		0xB3 0xD0
		0xB4 0x10
		0xB5 0x28
		0xB6 0xFD
		0xB7 0xF6
		0xB8 0xFD
		0xB9 0xDE
		0xBA 0xFD
		0xBB 0xF0
		0xBC 0x00
		0xBD 0xFF
		0xBE 0x01
		0xBF 0x5E
		0xC0 0x00
		0xC1 0x6E
		0xC2 0xF0
		0xC3 0x00
		0xC4 0x00
		0xC5 0x00
		0x13 0xBA
		0x18 0xF9
		0x1C 0x18
		0x35 0x00
		0x36 0x00
		0x3A 0x0A
		0x3B 0x50
		0x3C 0x0A
		0x3D 0x50
		0x3E 0x60
		0x94 0x10
		0x95 0xB0
		0x96 0x06
		0x2E 0x15
		0x0E 0xE0
		0x0F 0x1E
		0x10 0x00
		0x11 0xC1
		0xD0 0xE0
		0xD1 0x02
		0xD2 0x00
		0xD3 0xFF
		0xD4 0xFF
		0xD5 0x10
		0xD6 0x3C
		0xD7 0xFF
		0xD8 0x1E
		0xD9 0x60
		0xDA 0x7F
		0xDB 0xE0
		0xDC 0x00
		0xDB 0xFF
		0x76 0x08
		0x77 0x00
		0x79 0x02
		0x7A 0x00
		0xAA 0x32
		0xAB 0xC8
		0xAD 0x04
		0xAE 0x00
		>;
};

/* #include "../battery_common.dtsi" */              /* From battery_common.py */
#include <dt-bindings/battery/sec-battery.h>

&smd {
	sec_battery: battery {
		status = "okay";
		compatible = "samsung,sec-battery";
		battery,vendor = "Battery";
		battery,charger_name = "sec-direct-charger";
		battery,fuelgauge_name = "mtk-fg-battery";
		battery,technology = <2>; /* POWER_SUPPLY_TECHNOLOGY_LION */
		battery,chip_vendor = "NONE";

		battery,batt_data_version = <1>;

		battery,adc_check_count = <5>;
		battery,temp_check_type = <SEC_BATTERY_TEMP_CHECK_NONE>;
		battery,usb_temp_check_type = <SEC_BATTERY_TEMP_CHECK_NONE>;
		battery,chg_temp_check_type = <SEC_BATTERY_TEMP_CHECK_NONE>;
		battery,wpc_temp_check_type = <SEC_BATTERY_TEMP_CHECK_NONE>;
		battery,lrp_temp_check_type = <SEC_BATTERY_TEMP_CHECK_NONE>;

		battery,thermal_source = <SEC_BATTERY_THERMAL_SOURCE_NONE>; /* SEC_BATTERY_THERMAL_SOURCE_NONE */
		battery,usb_thermal_source = <SEC_BATTERY_THERMAL_SOURCE_NONE>; /* SEC_BATTERY_THERMAL_SOURCE_NONE */
		battery,chg_thermal_source = <SEC_BATTERY_THERMAL_SOURCE_NONE>; /* SEC_BATTERY_THERMAL_SOURCE_NONE */
		battery,wpc_thermal_source = <SEC_BATTERY_THERMAL_SOURCE_NONE>; /* SEC_BATTERY_THERMAL_SOURCE_NONE */

		battery,inbat_ocv_type =  <SEC_BATTERY_OCV_NONE>;

		battery,polling_time = <10 30 30 30 3600>;

		battery,cable_check_type = <SEC_BATTERY_CABLE_CHECK_PSY>;
		battery,cable_source_type = <SEC_BATTERY_CABLE_SOURCE_EXTERNAL>;
		battery,polling_type = <SEC_BATTERY_MONITOR_ALARM>; /* SEC_BATTERY_MONITOR_ALARM */
		battery,monitor_initial_count = <0>;

		battery,battery_check_type = <0>; /* SEC_BATTERY_CHECK_NONE */

		battery,ovp_uvlo_check_type = <SEC_BATTERY_OVP_UVLO_CHGPOLLING>; /* SEC_BATTERY_OVP_UVLO_CHGPOLLING */

		battery,temp_check_count = <1>;

		battery,usb_protection_temp = <610>;
		battery,temp_gap_bat_usb = <200>;
		battery,overheatlimit_threshold = <700>;
		battery,overheatlimit_recovery = <680>;
		battery,wire_warm_overheat_thresh = <500>;
		battery,wire_normal_warm_thresh = <420>;
		battery,wire_cool1_normal_thresh = <180>;
		battery,wire_cool2_cool1_thresh = <150>;
		battery,wire_cool3_cool2_thresh = <50>;
		battery,wire_cold_cool3_thresh = <0>;
		battery,wireless_warm_overheat_thresh = <500>;
		battery,wireless_normal_warm_thresh = <420>;
		battery,wireless_cool1_normal_thresh = <180>;
		battery,wireless_cool2_cool1_thresh = <150>;
		battery,wireless_cool3_cool2_thresh = <50>;
		battery,wireless_cold_cool3_thresh = <0>;
		battery,tx_high_threshold = <500>;
		battery,tx_high_recovery = <450>;
		battery,tx_low_threshold = <0>;
		battery,tx_low_recovery = <50>;

		battery,wire_warm_current = <1573>;	/* 0.36C */
		battery,wire_cool1_current = <3146>;	/* 0.72C */
		battery,wire_cool2_current = <1048>;	/* 0.24C */
		battery,wire_cool3_current = <437>;	/* 0.1C */
		battery,wireless_warm_current = <1048>;		/* 0.24C */
		battery,wireless_cool1_current = <3146>;	/* 0.72C */
		battery,wireless_cool2_current = <1048>;	/* 0.24C */
		battery,wireless_cool3_current = <437>;		/* 0.1C */

		battery,full_check_type = <SEC_BATTERY_FULLCHARGED_CHGPSY>;
		battery,full_check_type_2nd = <SEC_BATTERY_FULLCHARGED_CHGPSY>;
		battery,full_check_count = <1>;
		battery,chg_gpio_full_check = <0>;
		battery,chg_polarity_full_check = <1>;

		battery,chg_high_temp = <470>;
		battery,chg_high_temp_recovery = <450>;
		battery,chg_input_limit_current = <1000>;
		battery,chg_charging_limit_current = <1900>;

		battery,dchg_high_temp = <520>;
		battery,dchg_high_temp_recovery = <460>;
		battery,dchg_high_batt_temp = <400>;
		battery,dchg_high_batt_temp_recovery = <380>;
		battery,dchg_input_limit_current = <1000>;
		battery,dchg_charging_limit_current = <2000>;

		battery,wpc_temp_control_source = <TEMP_CONTROL_SOURCE_BAT_THM>;
		battery,wpc_high_temp = <400>;
		battery,wpc_high_temp_recovery = <380>;
		battery,wpc_input_limit_current = <800>;
		battery,wpc_charging_limit_current = <1000>;
		battery,wpc_temp_lcd_on_control_source = <TEMP_CONTROL_SOURCE_BAT_THM>;
		battery,wpc_lcd_on_input_limit_current = <800>;

		battery,wpc_store_high_temp = <360>;
		battery,wpc_store_high_temp_recovery = <340>;
		battery,wpc_store_charging_limit_current = <400>;
		battery,wpc_store_lcd_on_high_temp = <360>;
		battery,wpc_store_lcd_on_high_temp_rec = <300>;
		battery,wpc_store_lcd_on_charging_limit_current = <400>;

		battery,fcc_by_tx = <1200>;

		battery,sleep_mode_limit_current = <800>;
		battery,wc_full_input_limit_current = <100>;

		battery,ta_alert_wa;

		battery,mix_high_temp = <420>;
		battery,mix_high_chg_temp = <500>;
		battery,mix_high_temp_recovery = <390>;

		/* battery,enable_mix_v2; */
		/* if you want to use mix_v2 concept, add "battery,enable_mix_v2;" */
		battery,mix_v2_lrp_recov = <460>;
		battery,mix_v2_lrp_cond = <480>;
		battery,mix_v2_bat_cond = <480>;
		battery,mix_v2_chg_cond = <0>;	/* 0 means no use chg thm condition */
		battery,mix_v2_dchg_cond = <0>; /* 0 means no use dchg thm condition */

		battery,full_condition_type = <(SEC_BATTERY_FULL_CONDITION_NOTIMEFULL | SEC_BATTERY_FULL_CONDITION_VCELL)>;
		battery,full_condition_soc = <93>;
		battery,full_condition_vcell = <4250>;

		battery,recharge_check_count = <1>;
		battery,recharge_condition_type = <SEC_BATTERY_RECHARGE_CONDITION_VCELL>;
		battery,recharge_condition_soc = <98>;
		battery,recharge_condition_vcell = <4280>;

		battery,charging_reset_time = <0>;

		battery,chg_float_voltage = <4350>;

		battery,pre_afc_work_delay = <2000>;
		battery,pre_wc_afc_work_delay = <4000>;
		battery,pre_afc_input_current = <500>;
		battery,pre_wc_afc_input_current = <500>;
		battery,prepare_ta_delay = <0>; /* msec */

		battery,swelling_high_rechg_voltage = <4000>;
		battery,swelling_low_rechg_voltage = <4000>;

		battery,siop_icl = <1200>;
		battery,siop_fcc = <1800>;
		battery,siop_hv_icl = <700>;
		battery,siop_hv_icl_2nd = <550>;
		battery,siop_hv_fcc = <1800>;
		battery,siop_apdo_icl = <1000>;
		battery,siop_apdo_fcc = <2000>;

		battery,siop_wpc_icl = <600>;
		battery,siop_wpc_fcc = <1000 500 100>; /* siop_level 70 10 0 */
		battery,siop_hv_wpc_icl = <700>;
		battery,siop_hv_wpc_fcc = <1000 500 100>; /* siop_level 70 10 0 */
		battery,siop_store_hv_wpc_icl = <450>;
		battery,store_mode_buckoff;

		/* trig, recov */
		battery,temp_table_LRP_45W = <385 365>;

		battery,rp_current_rp1 = <500>;
		battery,rp_current_rp2 = <1500>;
		battery,rp_current_rp3 = <3000>;
		battery,rp_current_rdu_rp3 = <2100>;
		battery,rp_current_abnormal_rp3 = <1800>;

		battery,pd_charging_charge_power = <15000>;
		battery,max_charging_current = <2350>;

		battery,store_mode_charging_max = <70>;
		battery,store_mode_charging_min = <60>;

		battery,wireless_cc_cv = <85>;
		battery,wireless_otg_input_current = <900>;

		/* cycle, chg_float_voltage, recharge_condition_vcell, full_condition_vcell, full_condition_soc, step charging condition */
		battery,age_data = <0 4350 4280 4250 93
			300 4330 4260 4230 92
			400 4310 4240 4210 91
			700 4290 4220 4190 90
			1000 4240 4170 4140 89>;

		battery,max_input_voltage = <9000>; /* mV */
		battery,max_input_current = <3000>;  /* mA */

		battery,cisd_alg_index = <8>;
		battery,cisd_max_voltage_thr = <4400>; /* batttery ovp dettection voltage */
		battery,ignore_cisd_index = <0 0>;
		battery,ignore_cisd_index_d = <0 80>; /* Do not use BUCK_OFF_PER_DAY, DROP_SENSOR_PER_DAY */

		battery,expired_time = <10800>;
		battery,recharging_expired_time = <5400>;

		battery,battery_full_capacity = <3300>;

		battery,ttf_capacity = <3500>;
		battery,cv_data = <
				3228	864	1534
				3133	866	1524
				3067	872	1493
				3019	874	1483
				2929	879	1452
				2896	881	1442
				2843	883	1431
				2792	885	1421
				2754	887	1411
				2695	892	1380
				2660	893	1370
				2625	895	1360
				2580	897	1349
				2531	898	1339
				2492	902	1319
				2450	903	1309
				2410	905	1298
				2348	908	1278
				2296	909	1268
				2263	910	1257
				2214	915	1227
				2182	916	1216
				2147	919	1196
				2103	920	1186
				2051	922	1175
				2019	924	1155
				1981	927	1134
				1948	928	1124
				1911	930	1104
				1879	932	1093
				1834	933	1083
				1795	935	1063
				1761	938	1032
				1722	942	1001
				1689	944	981
				1649	946	960
				1592	948	940
				1532	950	919
				1493	954	878
				1462	955	868
				1410	958	827
				1362	959	817
				1338	960	807
				1291	964	756
				1264	968	715
				1237	968	704
				1213	969	694
				1169	974	633
				1127	975	622
				1105	975	612
				1073	980	541
				1049	982	510
				1010	983	489
				993	984	479
				972	986	448
				955	988	407
				932	990	387
				881	990	377
				864	996	356
				761	1000	307
				710	1000	297
				688	1000	287
				668	1000	235
				658	1000	215
				647	1000	184
				635	1000	153
				622	1000	123
				610	1000	92
				596	1000	61
				583	1000	31
				571	1000	0
				>;

#if 1
		io-channels = <&auxadc 3>;
		io-channel-names = "adc-chg-temp", "n/a", "n/a", "n/a", "n/a";
#endif
	};

	/* sec_battery_cable
	 *   0	UNKNOWN,
	 *   1	NONE,
	 *   2	PREPARE_TA,
	 *   3	TA,
	 *   4	USB,
	 *   5	USB_CDP,
	 *   6	9V_TA,
	 *   7	9V_ERR,
	 *   8	9V_UNKNOWN,
	 *   9	12V_TA,
	 *  10	WIRELESS,
	 *  11	HV_WIRELESS,
	 *  12	PMA_WIRELESS,
	 *  13	WIRELESS_PACK,
	 *  14	CABLE_WIRELESS_HV_PACK,
	 *  15	WIRELESS_STAND,
	 *  16	WIRELESS_HV_STAND,
	 *  17	QC20,
	 *  18	QC30,
	 *  19	PDIC,
	 *  20	UARTOFF,
	 *  21	OTG,
	 *  22	LAN_HUB,
	 *  23	POWER_SHARING,
	 *  24	HMT_CONNECTED,
	 *  25	HMT_CHARGE,
	 *  26	HV_TA_CHG_LIMIT,
	 *  27	WIRELESS_VEHICLE,
	 *  28	WIRELESS_HV_VEHICLE,
	 *  29	PREPARE_WIRELESS_HV,
	 *  30  TIMEOUT,
	 *  31  SMART_OTG,
	 *  32  SMART_NOTG,
	 *  33  WIRELESS_TX,
	 *  34	HV_WIRELESS_20,
	 *  35	HV_WIRELESS_20_LIMIT,
	 *  36	WIRELESS_FAKE,
	 *  37  PREPARE_WIRELESS_20,
	 *  38	CABLE_PDIC_APDO,
	 *  39  CABLE_POGO,
	 *  40  CABLE_POGO_9V,
	 *  41	CABLE_MAX,
	 */
	sec_battery_cable: cable-info {
		default_input_current = <1800>;
		default_charging_current = <2100>;
		full_check_current_1st = <350>;
		full_check_current_2nd = <200>;

		current_group_1 {
			cable_number = <
				SEC_BATTERY_CABLE_PREPARE_TA
				SEC_BATTERY_CABLE_PDIC
				SEC_BATTERY_CABLE_OTG
				SEC_BATTERY_CABLE_LAN_HUB
				SEC_BATTERY_CABLE_POWER_SHARING>;
			input_current = <500>;
			charging_current = <500>;
		};
		current_group_2 {
			cable_number = <
				SEC_BATTERY_CABLE_HMT_CHARGE
				SEC_BATTERY_CABLE_SMART_OTG>;
			input_current = <1000>;
			charging_current = <1000>;
		};
		current_group_3 {
			cable_number = <
				SEC_BATTERY_CABLE_USB_CDP
				SEC_BATTERY_CABLE_SMART_NOTG>;
			input_current = <1500>;
			charging_current = <1500>;
		};
		current_group_4 {
			cable_number = <SEC_BATTERY_CABLE_9V_TA SEC_BATTERY_CABLE_9V_ERR
				SEC_BATTERY_CABLE_9V_UNKNOWN SEC_BATTERY_CABLE_QC20 SEC_BATTERY_CABLE_QC30>;
			input_current = <1650>;
			charging_current = <2350>;
		};
		current_group_5 {
			cable_number = <SEC_BATTERY_CABLE_12V_TA>;
			input_current = <1650>;
			charging_current = <2350>;
		};
		current_group_6 {
			cable_number = <
				SEC_BATTERY_CABLE_WIRELESS
				SEC_BATTERY_CABLE_PMA_WIRELESS
				SEC_BATTERY_CABLE_WIRELESS_STAND
				SEC_BATTERY_CABLE_WIRELESS_VEHICLE
				SEC_BATTERY_CABLE_WIRELESS_FAKE>;
			input_current = <800>;
			charging_current = <2350>;
		};
		current_group_7 {
			cable_number = <SEC_BATTERY_CABLE_WIRELESS_PACK>;
			input_current = <700>;
			charging_current = <2350>;
		};
		current_group_8 {
			cable_number = <SEC_BATTERY_CABLE_HMT_CONNECTED>;
			input_current = <1000>;
			charging_current = <450>;
		};
		current_group_9 {
			cable_number = <SEC_BATTERY_CABLE_HV_TA_CHG_LIMIT>;
			input_current = <1800>;
			charging_current = <1800>;
		};
		current_group_10 {
			cable_number = <
				SEC_BATTERY_CABLE_HV_WIRELESS
				SEC_BATTERY_CABLE_WIRELESS_HV_PACK
				SEC_BATTERY_CABLE_WIRELESS_HV_STAND
				SEC_BATTERY_CABLE_WIRELESS_HV_VEHICLE
				SEC_BATTERY_CABLE_HV_WIRELESS_20_LIMIT>;
			input_current = <650>;
			charging_current = <2350>;
		};
		current_group_11 {
			cable_number = <
				SEC_BATTERY_CABLE_PREPARE_WIRELESS_HV
				SEC_BATTERY_CABLE_PREPARE_WIRELESS_20>;
			input_current = <500>;
			charging_current = <1200>;
		};
		current_group_12 {
			cable_number = <
				SEC_BATTERY_CABLE_NONE
				SEC_BATTERY_CABLE_USB
				SEC_BATTERY_CABLE_TIMEOUT>;
			input_current = <475>;
			charging_current = <550>;
		};
		current_group_13 {
			cable_number = <SEC_BATTERY_CABLE_HV_WIRELESS_20>;
			input_current = <1200>;
			charging_current = <2350>;
		};
		current_group_14 {
			cable_number = <SEC_BATTERY_CABLE_WIRELESS_TX>;
			input_current = <800>;
			charging_current = <2350>;
		};
	};
	sec_battery_wireless_power_info: wireless-power-info {
		count = <5>;
		current_group_0 {
			wireless_power_class = <2>;
			vout = <9000>;
			input_current_limit = <825>;
			fast_charging_current = <3150>;
			ttf_charge_current = <1500>;
			rx_power = <7500>;
		};
		current_group_1 {
			wireless_power_class = <2>;
			vout = <10000>;
			input_current_limit = <750>;
			fast_charging_current = <3150>;
			ttf_charge_current = <1500>;
			rx_power = <7500>;
		};
		current_group_2 {
			wireless_power_class = <2>;
			vout = <9000>;
			input_current_limit = <1200>;
			fast_charging_current = <3150>;
			ttf_charge_current = <2175>;
			rx_power = <12000>;
		};
		current_group_3 {
			wireless_power_class = <2>;
			vout = <11000>;
			input_current_limit = <1100>;
			fast_charging_current = <3150>;
			ttf_charge_current = <2100>;
			rx_power = <12000>;
		};
		current_group_4 {
			wireless_power_class = <2>;
			vout = <11000>;
			input_current_limit = <1300>;
			fast_charging_current = <3150>;
			ttf_charge_current = <2300>;
			rx_power = <15000>;
		};
	};
};

/* /home/dpi/qb5_8814/workspace/P4_1716/android/kernel/kmodule/battery/suwon/common/dts/a34x/battery_common.dtsi */
#define MAX_FV 4440
#define MAX_FCC 3000

#define DCHG_ICL 1100
#define DCHG_FCC 2200

&sec_battery {
		pinctrl-names = "default";

		battery,chip_vendor = "MTK";

		battery,temp_check_type = <SEC_BATTERY_TEMP_CHECK_ADC>;
		battery,chg_temp_check_type = <SEC_BATTERY_TEMP_CHECK_ADC>;
		battery,dchg_temp_check_type = <SEC_BATTERY_TEMP_CHECK_TEMP>;
		battery,lrp_temp_check_type = <SEC_BATTERY_TEMP_CHECK_TEMP>;

		battery,thermal_source = <SEC_BATTERY_THERMAL_SOURCE_FG_ADC>;
		battery,chg_thermal_source = <SEC_BATTERY_THERMAL_SOURCE_ADC>;
		battery,dchg_thermal_source = <SEC_BATTERY_THERMAL_SOURCE_ADC>;
		battery,dctp_by_cgtp;

		battery,temp_table_adc = <
					229 255 281 332 380 445 505 591 690 831
					933 1056 1202 1355 1511 1695 1834 1995 2133 2261
					2367 2464 2558
					>;
		battery,temp_table_data = <
					900 850 800 750 700 650 600 550 500 450
					400 350 300 250 200 150 100 50 0 (-50)
					(-100) (-150) (-200)
					>;

		battery,chg_temp_table_adc = <
					320 386 460 545 607 720 806 937 1139 1324
					1556 1780 2029 2285 2589 2892 3155 3328 3590 3828
					4029 4081 4095
					>;
		battery,chg_temp_table_data = <
					900 850 800 750 700 650 600 550 500 450
					400 350 300 250 200 150 100 50 0 (-50)
					(-100) (-150) (-200)
					>;

		battery,usb_protection;
		battery,temp_check_count = <1>;
		battery,wire_warm_overheat_thresh = <500>;
		battery,wire_normal_warm_thresh = <420>;
		battery,wire_cool1_normal_thresh = <180>;
		battery,wire_cool2_cool1_thresh = <150>;
		battery,wire_cool3_cool2_thresh = <50>;
		battery,wire_cold_cool3_thresh = <0>;

		battery,wire_warm_current = <3500>;	/* 0.72C */
		battery,wire_cool1_current = <MAX_FCC>; /* 0.72C */
		battery,wire_cool2_current = <1150>;	/* 0.24C */
		battery,wire_cool3_current = <450>;	/* 0.1C */

		battery,high_temp_topoff = <250>;
		battery,low_temp_topoff = <250>;
		battery,high_temp_float = <4200>;
		battery,low_temp_float = <MAX_FV>;

		battery,chg_high_temp = <590>;
		battery,chg_high_temp_recovery = <550>;
		battery,chg_input_limit_current = <1000>;
		battery,chg_charging_limit_current = <1900>;

		/* 45w pwr on, 45w pwr off, 25w pwr on, 25w pwr off */
		battery,dchg_high_temp = <1000 1000 590 590>;
		battery,dchg_high_temp_recovery = <1000 1000 550 550>;
		battery,dchg_high_batt_temp = <1000 1000 1000 1000>; /* DISABLED */
		battery,dchg_high_batt_temp_recovery = <1000 1000 1000 1000>; /* DISABLED */
		battery,dchg_input_limit_current = <DCHG_ICL>;
		battery,dchg_charging_limit_current = <DCHG_FCC>;
		battery,dchg_dc_in_swelling;

		/* trig_step2_LCD_OFF, recov_step2_LCD_OFF, trig_step1_LCD_OFF, recov_step1_LCD_OFF,
		   trig_step2_LCD_ON, recov_step2_LCD_ON, trig_step1_LCD_ON, recov_step1_LCD_ON,
		   st1_icl, st1_fcc, st2_icl, st2_fcc */
		battery,temp_table_LRP_NORMAL = <
							400 390 390 380
							390 380 380 370
							1000 2400 1200 1800>;
		battery,temp_table_LRP_25W = <
							410 400 390 380
							400 390 380 370
							1700 3400 1100 2200>;

		battery,mix_high_temp = <420>;
		battery,mix_high_chg_temp = <500>;
		battery,mix_high_temp_recovery = <390>;

		battery,full_check_type = <SEC_BATTERY_FULLCHARGED_FG_CURRENT>;
		battery,full_check_type_2nd = <SEC_BATTERY_FULLCHARGED_FG_CURRENT>;

		battery,full_condition_vcell = <4390>;
		battery,recharge_condition_vcell = <4370>;
		battery,chg_float_voltage = <MAX_FV>;

		battery,swelling_high_rechg_voltage = <4050>;
		battery,swelling_low_rechg_voltage = <4290>;

		battery,max_charging_current = <MAX_FCC>;
		battery,max_charging_charge_power = <25000>; /* 25W */

		/* cycle, chg_float_voltage, recharge_condition_vcell, full_condition_vcell, full_condition_soc */
		battery,age_data = <0 MAX_FV 4370 4390 93
			300 4420 4350 4370 92
			600 4400 4330 4350 91
			1001 4330 4260 4280 89>;

		battery,health_condition = <
			/* CYCLE ASOC */
			900 0  /* GOOD */
			1200 0 /* NORMAL */
			1500 0 /* AGED */
			>;

		/* direct step charging option */
		battery,dc_step_chg_type = <0xE9>;
		battery,dc_step_chg_charge_power = <22000>;
		battery,dc_step_chg_step = <3>;
		battery,dc_step_chg_cond_v_margin = <80>; /* mV */
		battery,dc_step_chg_cond_vol = <4130 4250 MAX_FV>; /* STEP_CHARGING_CONDITION_VOLTAGE */
		battery,dc_step_chg_cond_iin = <2290 1825 0>; /* STEP_CHARGING_CONDITION_INPUT_CURRENT */
		battery,dc_step_chg_iin_check_cnt = <3>;
		battery,dc_step_chg_cond_soc = <47 65 100>; /* STEP_CHARGING_CONDITION_SOC */
		battery,dc_step_chg_val_vfloat = <4130 4250 MAX_FV>; /* STEP_CHARGING_CONDITION_FLOAT_VOLTAGE */
		battery,dc_step_chg_val_iout = <5540 4580 3650>;

		battery,siop_scenarios = <20 0>;
		battery,siop_curr_type_num = <3>;
		/* nv, hv, fpdo */
		battery,siop_icl_20 = <1000 1000 1000>; /* 5W SIOP_DEFAULT 5W */
		battery,siop_fcc_20 = <SIOP_DEFAULT SIOP_DEFAULT SIOP_DEFAULT>;
		battery,siop_icl_0 = <1000 1000 1000>; /* 5W SIOP_DEFAULT 5W */
		battery,siop_fcc_0 = <SIOP_DEFAULT SIOP_DEFAULT SIOP_DEFAULT>;

		battery,standard_curr = <3690>;
		battery,expired_time = <9840>; /* 104 + 60 minutes */
		battery,recharging_expired_time = <5400>;
		battery,battery_full_capacity = <5000>;
		battery,cisd_max_voltage_thr = <5000>; /* batttery ovp dettection voltage */

		battery,inbat_ocv_type =  <SEC_BATTERY_OCV_VOLT_FROM_PMIC>;
		battery,slowcharging_usb_bootcomplete;
		battery,dynamic_cv_factor;

		battery,ttf_hv_charge_current = <2085>;
		battery,ttf_dc25_charge_current = <3600>;
		battery,ttf_capacity = <3875>;
		battery,cv_data = <
				3590	830	1713
				3247	850	1599
				2720	870	1475
				2166	890	1319
				1701	910	1143
				1261	930	926
				940	950	676
				671	970	381
				554	990	93
				517	1000	0
					>;
};

&sec_battery_cable {
		full_check_current_1st = <490>;
		full_check_current_2nd = <250>;

		current_group_4 {
			charging_current = <MAX_FCC>;
		};
		current_group_5 {
			charging_current = <MAX_FCC>;
		};
		current_group_6 {
			charging_current = <MAX_FCC>;
		};
		current_group_7 {
			charging_current = <MAX_FCC>;
		};
		current_group_10 {
			charging_current = <MAX_FCC>;
		};
};

/* #include "../sensorhub_mt6877_shub.dtsi" */       /* From sensorhub_mt6877_shub.py */
/ {
	fragment@model {
		target-path = "/";
		__overlay__ {
			shub {
				compatible = "shub";
			};
		};
	};
};

/* /home/dpi/qb5_8814/workspace/P4_1716/android/kernel/kmodule/sensorhub/mtk/mt6877_shub/dts/sensorhub_mt6877_shub.a34x.dtsi */
/ {
	fragment@model {
		target-path = "/";
		__overlay__ {
			shub {
				acc-motor-coef = <5>;
				acc-lsm6dsotr-position = <5>;
	
				mag-ak09918c-position = <7>;
				mag-ak09918c-array = /bits/ 8 <0 0 0 0 0 0 0 0 0
								0 0 0 0 0 0 0 0 0
								0 0 0 0 0 0 0 0 0>;
				mag-mxg4300s-position = <4>;
				mag-mxg4300s-array = /bits/ 8 <39 16 0 0 0 0 0 0 39
								16 0 0 0 0 0 0 39 16
								0 0 0 0 0 0 0 0 0>;
				fcd-axis = <1>;
				fcd-threshold = <(500)>;
				light-position = /bits/ 32 <26 52 3 67 2 0>;
				brightness-array-len = <11>;
				brightness-array = /bits/ 32 <19 48 54 58 63 67 70 73 75 77 100>;
			};
		};
	};
};

/* /home/dpi/qb5_8814/workspace/P4_1716/android/kernel/kmodule/sensorhub/mtk/mt6877_shub/dts/sensorhub_mt6877_shub.a34x.03.dtsi */
/ {
	fragment@model {
		target-path = "/";
		__overlay__ {
			shub {
				acc-lsm6dsotr-position = <7>;
				mag-mxg4300s-array = /bits/ 8 <40 230 4 186 0 120 4 186 33 212 255 176 0 120 255 176 42 118 0 0 0 0 0 0 0 0 0>;
			};
		};
	};
};

/* revision devicetree for general */
#include "mt6877.a34x_eur_open.03.dtsi"

/ {
	compatible = "Samsung,A34x EUR OPEN 03","Mediatek,MT6877";
	dtbo-hw_rev = <3>;
	dtbo-hw_rev_end = <3>;
};
